AUTOSAR XML (schema 4-3-0)
package /Impl_SWC_INP_ARPkg
  swc implementation Impl_SWC_INP_type: programming-language=C, sw-version=1.0.0, vendor-id=0, behavior=SWC_INP_type_IB
    code-descriptors:
      code SRC: artifact-descriptors=autosar-engineering-object={short-label=EngObject, category=SWSRC}
    resource consumption ResourceConsumption
      memory section Mem_SWC_INP_CAL: size=0, sw-addrmethod=CAL, symbol=CAL
      memory section Mem_SWC_INP_CODE: size=0, sw-addrmethod=CODE, symbol=CODE
package /Impl_Type_INP_ARPkg
  18 x impl type:
    BINP_CAN1_outputs: category=STRUCTURE
      134 x element, all with category=TYPE_REFERENCE:
        VINP_CANMsgValidABM1_flg: implementation-data-type=boolean
        VINP_CANMsgValidEPB1_flg: implementation-data-type=boolean
        VINP_CANMsgValidEPS1_flg: implementation-data-type=boolean
        VINP_CANMsgValidESC1_flg: implementation-data-type=boolean
        VINP_CANMsgValidESC5_flg: implementation-data-type=boolean
        VINP_CANMsgValideBST1_flg: implementation-data-type=boolean
        VINP_ABM1CSErr_flg: implementation-data-type=boolean
        VINP_ABM1RCErr_flg: implementation-data-type=boolean
        VINP_ABMPassengerODSSta_flg: implementation-data-type=boolean
        VINP_ABMRearPassengerCTRODSSta_flg: implementation-data-type=boolean
        VINP_ABMRearPassengerLHODSSta_flg: implementation-data-type=boolean
        VINP_ABMRearPassengerRHODSSta_flg: implementation-data-type=boolean
        VINP_AirBagFailCmd_flg: implementation-data-type=boolean
        VINP_ChecksumABM1_enum: implementation-data-type=uint8
        VINP_CrashOutputSts_enum: implementation-data-type=uint8
        VINP_DriverSeatBeltCmd_flg: implementation-data-type=boolean
        VINP_LifeCountABM1_enum: implementation-data-type=uint8
        VINP_PABSwitchCmd_flg: implementation-data-type=boolean
        VINP_PsngrSeatBeltCmd_flg: implementation-data-type=boolean
        VINP_RCenterSeatBeltCmd_flg: implementation-data-type=boolean
        VINP_RDriverSeatBeltCmd_flg: implementation-data-type=boolean
        VINP_RPsngrSeatBeltCmd_flg: implementation-data-type=boolean
        VINP_TLHPsngrSeatBeltCmd_flg: implementation-data-type=boolean
        VINP_TRHPsngrSeatBeltCmd_flg: implementation-data-type=boolean
        VINP_EPB1CSErr_flg: implementation-data-type=boolean
        VINP_EPB1RCErr_flg: implementation-data-type=boolean
        VINP_DOASta_flg: implementation-data-type=boolean
        VINP_EPB1RC_enum: implementation-data-type=uint8
        VINP_EPBCarWashMode_flg: implementation-data-type=boolean
        VINP_EPBErrSta_enum: implementation-data-type=uint8
        VINP_EPBExtApplyAvail_flg: implementation-data-type=boolean
        VINP_EPBExtReleaseAvail_flg: implementation-data-type=boolean
        VINP_EPBSta_enum: implementation-data-type=uint8
        VINP_EPS1CSErr_flg: implementation-data-type=boolean
        VINP_EPS1RCErr_flg: implementation-data-type=boolean
        VINP_DriIntend_enum: implementation-data-type=uint8
        VINP_EPSAOIControl_enum: implementation-data-type=uint8
        VINP_EPSRC_enum: implementation-data-type=uint8
        VINP_EpasFailed_enum: implementation-data-type=uint8
        VINP_SASAngle_Deg: implementation-data-type=float32
        VINP_SASCAL_flg: implementation-data-type=boolean
        VINP_SASSpeed_degps: implementation-data-type=float32
        VINP_SASSpeedValid_flg: implementation-data-type=boolean
        VINP_SASV_flg: implementation-data-type=boolean
        VINP_ESC1CSErr_flg: implementation-data-type=boolean
        VINP_ESC1RCErr_flg: implementation-data-type=boolean
        VINP_ABSActive_flg: implementation-data-type=boolean
        VINP_ABSFailed_flg: implementation-data-type=boolean
        VINP_ABSWnlmpSta_flg: implementation-data-type=boolean
        VINP_AVHActive_flg: implementation-data-type=boolean
        VINP_AVHFailed_flg: implementation-data-type=boolean
        VINP_AmberWnlmpSta_flg: implementation-data-type=boolean
        VINP_BTCSActive_flg: implementation-data-type=boolean
        VINP_EBDActive_flg: implementation-data-type=boolean
        VINP_EBDFailed_flg: implementation-data-type=boolean
        VINP_ESC1CS_enum: implementation-data-type=uint8
        VINP_ESC1RC_enum: implementation-data-type=uint8
        VINP_ESCActive_flg: implementation-data-type=boolean
        VINP_ESCBeepReq_flg: implementation-data-type=boolean
        VINP_ESCFailed_flg: implementation-data-type=boolean
        VINP_ESCOFFStatus_enum: implementation-data-type=uint8
        VINP_ESCOfflmpSta_flg: implementation-data-type=boolean
        VINP_ESCWnlmpSta_enum: implementation-data-type=uint8
        VINP_ESSActive_flg: implementation-data-type=boolean
        VINP_FrPTCSActive_flg: implementation-data-type=boolean
        VINP_FrntAxlTrqReqDrv_Nm: implementation-data-type=float32
        VINP_GRADE_Deg: implementation-data-type=float32
        VINP_HBBActive_flg: implementation-data-type=boolean
        VINP_HBBFailed_flg: implementation-data-type=boolean
        VINP_HDDActive_flg: implementation-data-type=boolean
        VINP_HDDFailed_flg: implementation-data-type=boolean
        VINP_HSAActive_flg: implementation-data-type=boolean
        VINP_HSAFailed_flg: implementation-data-type=boolean
        VINP_LFPulseCount_enum: implementation-data-type=uint8
        VINP_LFPulseCountV_flg: implementation-data-type=boolean
        VINP_LFRawWhlSpeed_kph: implementation-data-type=float32
        VINP_LFRawWhlSpeedV_flg: implementation-data-type=boolean
        VINP_LFWhlRotDir_enum: implementation-data-type=uint8
        VINP_LRPulseCount_enum: implementation-data-type=uint8
        VINP_LRPulseCountV_flg: implementation-data-type=boolean
        VINP_LRRawWhlSpeed_kph: implementation-data-type=float32
        VINP_LRRawWhlSpeedV_flg: implementation-data-type=boolean
        VINP_LRWhlRotDir_enum: implementation-data-type=uint8
        VINP_PBAActive_flg: implementation-data-type=boolean
        VINP_PBAFailed_flg: implementation-data-type=boolean
        VINP_RFPulseCount_enum: implementation-data-type=uint8
        VINP_RFPulseCountV_flg: implementation-data-type=boolean
        VINP_RFRawWhlSpeed_kph: implementation-data-type=float32
        VINP_RFRawWhlSpeedV_flg: implementation-data-type=boolean
        VINP_RFWhlRotDir_enum: implementation-data-type=uint8
        VINP_RRPulseCount_enum: implementation-data-type=uint8
        VINP_RRPulseCountV_flg: implementation-data-type=boolean
        VINP_RRRawWhlSpeed_kph: implementation-data-type=float32
        VINP_RRRawWhlSpeedV_flg: implementation-data-type=boolean
        VINP_RRWhlRotDir_enum: implementation-data-type=uint8
        VINP_RearAxlTrqReqDrv_Nm: implementation-data-type=float32
        VINP_RedWnlmpSta_flg: implementation-data-type=boolean
        VINP_RrPTCSActive_flg: implementation-data-type=boolean
        VINP_TCSActive_flg: implementation-data-type=boolean
        VINP_TCSFailed_flg: implementation-data-type=boolean
        VINP_VehSpeed_kph: implementation-data-type=float32
        VINP_ESC5CSErr_flg: implementation-data-type=boolean
        VINP_ESC5RCErr_flg: implementation-data-type=boolean
        VINP_ACCAvail_flg: implementation-data-type=boolean
        VINP_AEBAvail_flg: implementation-data-type=boolean
        VINP_ActBrkLampSta_flg: implementation-data-type=boolean
        VINP_BrkDiscTempSta_flg: implementation-data-type=boolean
        VINP_BrkPedalPos_pct: implementation-data-type=float32
        VINP_BrkPedalPosSta_flg: implementation-data-type=boolean
        VINP_BrkSwSta_flg: implementation-data-type=boolean
        VINP_BrkSwV_flg: implementation-data-type=boolean
        VINP_ESC5CS_enum: implementation-data-type=uint8
        VINP_ESC5RC_enum: implementation-data-type=uint8
        VINP_ESCADASSta_enum: implementation-data-type=uint8
        VINP_ESCAPSSta_enum: implementation-data-type=uint8
        VINP_ESCStandstill_flg: implementation-data-type=boolean
        VINP_FrRBCActive_flg: implementation-data-type=boolean
        VINP_FrntAxlTrqReqBrk_Nm: implementation-data-type=float32
        VINP_LatAccel_Gps: implementation-data-type=float32
        VINP_LatAccelV_flg: implementation-data-type=boolean
        VINP_LongAccel_Gps: implementation-data-type=float32
        VINP_LongAccelV_flg: implementation-data-type=boolean
        VINP_MCPressure_bar: implementation-data-type=float32
        VINP_MCPressureV_flg: implementation-data-type=boolean
        VINP_MeterIndVehSpeed_kph: implementation-data-type=float32
        VINP_RDCActive_enum: implementation-data-type=uint8
        VINP_RearAxlTrqReqBrk_Nm: implementation-data-type=float32
        VINP_RrRBCActive_flg: implementation-data-type=boolean
        VINP_YawRate_degps: implementation-data-type=float32
        VINP_YawRateV_flg: implementation-data-type=boolean
        VINP_LowBrakeFluidSta_flg: implementation-data-type=boolean
        VINP_eBSTAmberWnlmpSta_flg: implementation-data-type=boolean
        VINP_eBSTBeepReq_flg: implementation-data-type=boolean
        VINP_eBSTRedWnlmpSta_flg: implementation-data-type=boolean
    BINP_CAN2_outputs: category=STRUCTURE
      196 x element, all with category=TYPE_REFERENCE:
        VINP_CANMsgValidHMI1_flg: implementation-data-type=boolean
        VINP_CANMsgValidIVI{1..3}_flg: implementation-data-type=boolean
        VINP_CANMsgValidMETER1_flg: implementation-data-type=boolean
        VINP_HMIACAirIntMCmd_flg: implementation-data-type=boolean
        VINP_HMIACAirIntPCmd_flg: implementation-data-type=boolean
        VINP_HMIACAutoBtnCmd_flg: implementation-data-type=boolean
        VINP_HMIACBtnCmd_flg: implementation-data-type=boolean
        VINP_HMIACFrDefogBtnCmd_flg: implementation-data-type=boolean
        VINP_HMIACRecycleBtnCmd_flg: implementation-data-type=boolean
        VINP_HMIACWindDirMCmd_flg: implementation-data-type=boolean
        VINP_HMIACWindDirPCmd_flg: implementation-data-type=boolean
        VINP_HMIAutoInterLightCmd_flg: implementation-data-type=boolean
        VINP_HMIBCMPostDefogBtnCmd_flg: implementation-data-type=boolean
        VINP_HMIZLSetTMCmd_flg: implementation-data-type=boolean
        VINP_HMIZLSetTPCmd_flg: implementation-data-type=boolean
        VINP_HMIZRSetTMCmd_flg: implementation-data-type=boolean
        VINP_HMIZRSetTPCmd_flg: implementation-data-type=boolean
        VINP_AmbLighLowBatAlertSW_flg: implementation-data-type=boolean
        VINP_AmbLighSafetyAlertSW_flg: implementation-data-type=boolean
        VINP_AmbLightBrightnessSet_enum: implementation-data-type=uint8
        VINP_AmbLightColorSet_enum: implementation-data-type=uint8
        VINP_AmbLightDimInDarkSW_flg: implementation-data-type=boolean
        VINP_AmbLightSW_flg: implementation-data-type=boolean
        VINP_AmbLightWlcmLightSW_flg: implementation-data-type=boolean
        VINP_FCPFrEvtBtnACMaxReq_flg: implementation-data-type=boolean
        VINP_FCPFrEvtBtnACReq_flg: implementation-data-type=boolean
        VINP_FCPFrEvtBtnAutoReq_flg: implementation-data-type=boolean
        VINP_FCPFrEvtBtnSyncReq_flg: implementation-data-type=boolean
        VINP_IVIAutoWipHSpdSWCmd_flg: implementation-data-type=boolean
        VINP_IVICLWinLockDoorSWSta_flg: implementation-data-type=boolean
        VINP_IVICreateAccReqSta_enum: implementation-data-type=uint8
        VINP_IVIDelAccReqSta_enum: implementation-data-type=uint8
        VINP_IVIDrivingLockSWSta_flg: implementation-data-type=boolean
        VINP_IVIEPSForceCmd_enum: implementation-data-type=uint8
        VINP_IVIFrTrunkUnlockReqSta_flg: implementation-data-type=boolean
        VINP_IVILinkAccReqSta_flg: implementation-data-type=boolean
        VINP_IVILinkAccSta_enum: implementation-data-type=uint8
        VINP_IVILinkKeySta_enum: implementation-data-type=uint8
        VINP_IVILocatedSTA_enum: implementation-data-type=uint8
        VINP_IVILockSoundSWSta_flg: implementation-data-type=boolean
        VINP_IVIMirrorFoldedSWSta_flg: implementation-data-type=boolean
        VINP_IVISWCVibModeSta_enum: implementation-data-type=uint8
        VINP_IVISilentChrgAlertSta_flg: implementation-data-type=boolean
        VINP_IVIStoppingUnlockSWSta_flg: implementation-data-type=boolean
        VINP_IVITimeCheck_enum: implementation-data-type=uint8
        VINP_IVITimeDay_DAY: implementation-data-type=float32
        VINP_IVITimeHour_hr: implementation-data-type=float32
        VINP_IVITimeMinute_min: implementation-data-type=float32
        VINP_IVITimeMonth_MONTH: implementation-data-type=float32
        VINP_IVITimeSecond_s: implementation-data-type=float32
        VINP_IVITimeYear_YEAR: implementation-data-type=float32
        VINP_IVIWPTCSWSta_flg: implementation-data-type=boolean
        VINP_IVIsigScreenReqSta_flg: implementation-data-type=boolean
        VINP_LINKtoDrive_flg: implementation-data-type=boolean
        VINP_OpenDrOpenWdoSW_flg: implementation-data-type=boolean
        VINP_PWCONTINUEUSE_flg: implementation-data-type=boolean
        VINP_SmartEcoModeSW_flg: implementation-data-type=boolean
        VINP_UserSet_enum: implementation-data-type=uint8
        VINP_ACChgCurSet_A: implementation-data-type=float32
        VINP_AVMErrSTA_flg: implementation-data-type=boolean
        VINP_AVMOFFRecButt_flg: implementation-data-type=boolean
        VINP_AVMParkingmode_enum: implementation-data-type=uint8
        VINP_AVMparkingcancel_enum: implementation-data-type=uint8
        VINP_AVMparkingexcute_enum: implementation-data-type=uint8
        VINP_ApproachUnlockSW_flg: implementation-data-type=boolean
        VINP_CAASSw_enum: implementation-data-type=uint8
        VINP_CDLLockButt_flg: implementation-data-type=boolean
        VINP_CDLUnlockButt_flg: implementation-data-type=boolean
        VINP_DSEATantiset_flg: implementation-data-type=boolean
        VINP_DSEATentryfunset_flg: implementation-data-type=boolean
        VINP_DSEATventreq_enum: implementation-data-type=uint8
        VINP_Distanceunit_flg: implementation-data-type=boolean
        VINP_ESCSWCmd_enum: implementation-data-type=uint8
        VINP_FSOffSw_enum: implementation-data-type=uint8
        VINP_FollowMeSW_flg: implementation-data-type=boolean
        VINP_GPSLAT_s: implementation-data-type=float32
        VINP_GPSLONG_enum: implementation-data-type=uint32
        VINP_HeadLampSW_enum: implementation-data-type=uint8
        VINP_HoodLatchSW_enum: implementation-data-type=uint8
        VINP_IVIACCAdaptiveSta_flg: implementation-data-type=boolean
        VINP_IVIAirIntZ3Cmd_enum: implementation-data-type=uint8
        VINP_IVICarWashModeCmd_flg: implementation-data-type=boolean
        VINP_IVIChargePortSWSta_flg: implementation-data-type=boolean
        VINP_IVICreepSWReq_flg: implementation-data-type=boolean
        VINP_IVIDSEATHeaterCmd_enum: implementation-data-type=uint8
        VINP_IVIDSEATFroEdgeHeightCmd_enum: implementation-data-type=uint8
        VINP_IVIDSEATHeightCmd_enum: implementation-data-type=uint8
        VINP_IVIDSEATMemory1Sta_flg: implementation-data-type=boolean
        VINP_IVIDSEATMemory2Sta_flg: implementation-data-type=boolean
        VINP_IVIDSEATMemoryOPTCLSSta_flg: implementation-data-type=boolean
        VINP_IVIDSEATReclineCmd_enum: implementation-data-type=uint8
        VINP_IVIDSEATSlideCmd_enum: implementation-data-type=uint8
        VINP_IVIFGSAirIntCmd_enum: implementation-data-type=uint8
        VINP_IVIFGSChCmd_enum: implementation-data-type=uint8
        VINP_IVIIONSWCmd_flg: implementation-data-type=boolean
        VINP_IVIISAOffsetSpd_enum: implementation-data-type=uint8
        VINP_IVINightModeSta_flg: implementation-data-type=boolean
        VINP_IVIPSEATHeaterCmd_enum: implementation-data-type=uint8
        VINP_IVIPSEATReclineCmd_enum: implementation-data-type=uint8
        VINP_IVIPSEATSlideCmd_enum: implementation-data-type=uint8
        VINP_IVIPTGModeSW_enum: implementation-data-type=uint8
        VINP_IVIPTGOpenHeight_enum: implementation-data-type=uint8
        VINP_IVIPTGStaSW_enum: implementation-data-type=uint8
        VINP_IVIPTGUSStaSW_flg: implementation-data-type=boolean
        VINP_IVIPWModeReq_enum: implementation-data-type=uint8
        VINP_IVIPwrLockSW_enum: implementation-data-type=uint8
        VINP_IVIPwroffreq_flg: implementation-data-type=boolean
        VINP_IVIRRDefReq_flg: implementation-data-type=boolean
        VINP_IVIReqV2L_enum: implementation-data-type=uint8
        VINP_IVISWCRUndefinedSta_enum: implementation-data-type=uint8
        VINP_IVIScreen_enum: implementation-data-type=uint8
        VINP_IVIStartChgreq_flg: implementation-data-type=boolean
        VINP_IVIStatus_flg: implementation-data-type=boolean
        VINP_IVIStopChgreq_flg: implementation-data-type=boolean
        VINP_IVITrailerCheckReqSta_flg: implementation-data-type=boolean
        VINP_IVITrailerModeSWSta_flg: implementation-data-type=boolean
        VINP_IVITriggerreq_flg: implementation-data-type=boolean
        VINP_IVIUnlockChgreq_flg: implementation-data-type=boolean
        VINP_IVIWIMAINSW_flg: implementation-data-type=boolean
        VINP_LDrvControlCommand_pct: implementation-data-type=float32
        VINP_LPasControlCommand_pct: implementation-data-type=float32
        VINP_LRLDControlCommand_pct: implementation-data-type=float32
        VINP_LRRDControlCommand_pct: implementation-data-type=float32
        VINP_LightShowStartReq_flg: implementation-data-type=boolean
        VINP_LightShowStopReq_flg: implementation-data-type=boolean
        VINP_MFRDNBrightReq_pct: implementation-data-type=float32
        VINP_OFFACMODE_enum: implementation-data-type=uint8
        VINP_PSEATventreq_enum: implementation-data-type=uint8
        VINP_PerdV2L_enum: implementation-data-type=uint8
        VINP_RFogLampSW_flg: implementation-data-type=boolean
        VINP_RollModeSWCmd_enum: implementation-data-type=uint8
        VINP_RoomLampMode_flg: implementation-data-type=boolean
        VINP_SOCADJBUTT_flg: implementation-data-type=boolean
        VINP_SOCLimitSet_pct: implementation-data-type=float32
        VINP_SOCV2LLimit_pct: implementation-data-type=float32
        VINP_SchedChgStart_flg: implementation-data-type=boolean
        VINP_SchedChgStop_flg: implementation-data-type=boolean
        VINP_SchedChgbutt_flg: implementation-data-type=boolean
        VINP_SchedChglimit_pct: implementation-data-type=float32
        VINP_SchedChgwake_flg: implementation-data-type=boolean
        VINP_SenstivityPosition_enum: implementation-data-type=uint8
        VINP_SetUnlockSingle_flg: implementation-data-type=boolean
        VINP_TCSSWCmd_enum: implementation-data-type=uint8
        VINP_TPMSCaliButt_flg: implementation-data-type=boolean
        VINP_TPMSResButt_flg: implementation-data-type=boolean
        VINP_TurnSwTimeSet_enum: implementation-data-type=uint8
        VINP_WalkawayLockSW_flg: implementation-data-type=boolean
        VINP_WlcmLightMode_enum: implementation-data-type=uint8
        VINP_sigAirIntenZon1Req_enum: implementation-data-type=uint8
        VINP_sigDfrstReq_flg: implementation-data-type=boolean
        VINP_sigFaceReq_flg: implementation-data-type=boolean
        VINP_sigFootReq_flg: implementation-data-type=boolean
        VINP_sigRecircReq_flg: implementation-data-type=boolean
        VINP_sigSetTempZon1Req_C: implementation-data-type=float32
        VINP_sigSetTempZon2Req_C: implementation-data-type=float32
        VINP_IVICLBlowerYSta_pct: implementation-data-type=float32
        VINP_IVICLBlowerZSta_pct: implementation-data-type=float32
        VINP_IVICRBlowerYSta_pct: implementation-data-type=float32
        VINP_IVICRBlowerZSta_pct: implementation-data-type=float32
        VINP_IVIHMICustmiFunSta_enum: implementation-data-type=uint8
        VINP_IVIHMICustmiKEYSta_enum: implementation-data-type=uint8
        VINP_IVILBlowerModeSta_enum: implementation-data-type=uint8
        VINP_IVILBlowerYSta_pct: implementation-data-type=float32
        VINP_IVILBlowerZSta_pct: implementation-data-type=float32
        VINP_IVILSEATventCmd_enum: implementation-data-type=uint8
        VINP_IVIMLFMostCmd_flg: implementation-data-type=boolean
        VINP_IVIMLFootLiftCmd_enum: implementation-data-type=uint8
        VINP_IVIMLNapModeCmd_flg: implementation-data-type=boolean
        VINP_IVIMLReclinerCmd_enum: implementation-data-type=uint8
        VINP_IVIMLRestoreCmd_flg: implementation-data-type=boolean
        VINP_IVIMLSEATventCmd_enum: implementation-data-type=uint8
        VINP_IVIMLSeatLiftCmd_enum: implementation-data-type=uint8
        VINP_IVIMLSldRestoreCmd_flg: implementation-data-type=boolean
        VINP_IVIMLSliderCmd_enum: implementation-data-type=uint8
        VINP_IVIMLZeroGravityCmd_flg: implementation-data-type=boolean
        VINP_IVIMRFMostCmd_flg: implementation-data-type=boolean
        VINP_IVIMRFootLiftCmd_enum: implementation-data-type=uint8
        VINP_IVIMRNapModeCmd_flg: implementation-data-type=boolean
        VINP_IVIMRReclinerCmd_enum: implementation-data-type=uint8
        VINP_IVIMRRestoreCmd_flg: implementation-data-type=boolean
        VINP_IVIMRSEATventCmd_enum: implementation-data-type=uint8
        VINP_IVIMRSeatLiftCmd_enum: implementation-data-type=uint8
        VINP_IVIMRSldRestoreCmd_flg: implementation-data-type=boolean
        VINP_IVIMRSliderCmd_enum: implementation-data-type=uint8
        VINP_IVIMRZeroGravityCmd_flg: implementation-data-type=boolean
        VINP_IVIRBlowerModeSta_enum: implementation-data-type=uint8
        VINP_IVIRBlowerYSta_pct: implementation-data-type=float32
        VINP_IVIRBlowerZSta_pct: implementation-data-type=float32
        VINP_IVIRSEATventCmd_enum: implementation-data-type=uint8
        VINP_IVISnowModeCmd_flg: implementation-data-type=boolean
        VINP_IVIUserTakeOverAPSSta_flg: implementation-data-type=boolean
        VINP_IVIZon1WindDirSWReqSta_flg: implementation-data-type=boolean
        VINP_METERKPHCalcu_kph: implementation-data-type=float32
        VINP_ODOMETER_km: implementation-data-type=float32
    BINP_CAN3_outputs: category=STRUCTURE
      298 x element, all with category=TYPE_REFERENCE:
        VINP_CANMsgValidBMS1_flg: implementation-data-type=boolean
        VINP_CANMsgValidBMS{3..6}_flg: implementation-data-type=boolean
        VINP_CANMsgValidBMS8_flg: implementation-data-type=boolean
        VINP_CANMsgValidCCU1_flg: implementation-data-type=boolean
        VINP_CANMsgValidCCU2_flg: implementation-data-type=boolean
        VINP_CANMsgValidEBM1_flg: implementation-data-type=boolean
        VINP_CANMsgValidMCUBF1_flg: implementation-data-type=boolean
        VINP_CANMsgValidMCUBF2_flg: implementation-data-type=boolean
        VINP_CANMsgValidMCUBR1_flg: implementation-data-type=boolean
        VINP_CANMsgValidMCUBR2_flg: implementation-data-type=boolean
        VINP_CANMsgValidMCUNF{1..3}_flg: implementation-data-type=boolean
        VINP_CANMsgValidMCUNR{1..3}_flg: implementation-data-type=boolean
        VINP_CANMsgValidShifter1_flg: implementation-data-type=boolean
        VINP_CANMsgValidShifter2_flg: implementation-data-type=boolean
        VINP_BMS1CSErr_flg: implementation-data-type=boolean
        VINP_BMS1RCErr_flg: implementation-data-type=boolean
        VINP_BMSChckSum1_enum: implementation-data-type=uint8
        VINP_BMSRolCnct1_enum: implementation-data-type=uint8
        VINP_HVBPwrAvailChrg_kW: implementation-data-type=float32
        VINP_HVBPwrAvailChrg30_kW: implementation-data-type=float32
        VINP_HVBPwrAvailChrg60_kW: implementation-data-type=float32
        VINP_HVBPwrAvailDchrg_kW: implementation-data-type=float32
        VINP_HVBPwrAvailDchrg30_kW: implementation-data-type=float32
        VINP_HVBPwrAvailDchrg60_kW: implementation-data-type=float32
        VINP_HVBattCurr_A: implementation-data-type=float32
        VINP_HVBattVolt_V: implementation-data-type=float32
        VINP_ACChrgCurrDis_A: implementation-data-type=float32
        VINP_FireDetErr_flg: implementation-data-type=boolean
        VINP_HVBChrgPwr_kWh: implementation-data-type=float32
        VINP_HVBChrgPwrTotal_kWh: implementation-data-type=float32
        VINP_HVBDrvPwr_kWh: implementation-data-type=float32
        VINP_HVBDrvPwrTotal_kWh: implementation-data-type=float32
        VINP_HVBFullChrgPwr_kWh: implementation-data-type=float32
        VINP_HVBIsoImpedenceN_Megaohm: implementation-data-type=float32
        VINP_HVBIsoImpedenceP_Megaohm: implementation-data-type=float32
        VINP_HVBSOH_pct: implementation-data-type=float32
        VINP_HVBattErr_flg: implementation-data-type=boolean
        VINP_HVBattPackVolt_V: implementation-data-type=float32
        VINP_HVBattSOC_pct: implementation-data-type=float32
        VINP_HVBattSOCDis_pct: implementation-data-type=float32
        VINP_RemainChrgTime_min: implementation-data-type=float32
        VINP_CellTempAvg_C: implementation-data-type=float32
        VINP_HVBCellVoltMax_mV: implementation-data-type=float32
        VINP_HVBCellVoltMin_mV: implementation-data-type=float32
        VINP_HVBMTempMax_C: implementation-data-type=float32
        VINP_HVBMTempMin_C: implementation-data-type=float32
        VINP_MaxCellTempNum_enum: implementation-data-type=uint8
        VINP_MaxCellVoltNum_enum: implementation-data-type=uint8
        VINP_MinCellTempNum_enum: implementation-data-type=uint8
        VINP_MinCellVoltNum_enum: implementation-data-type=uint8
        VINP_HVInVolt_V: implementation-data-type=float32
        VINP_LVBattDet12V_V: implementation-data-type=float32
        VINP_OBCACCSLimit_A: implementation-data-type=float32
        VINP_OBCDCCurLm_A: implementation-data-type=float32
        VINP_OBCDCVoltLm_V: implementation-data-type=float32
        VINP_BMS6CSErr_flg: implementation-data-type=boolean
        VINP_BMS6RCErr_flg: implementation-data-type=boolean
        VINP_BMSChckSum_enum: implementation-data-type=uint8
        VINP_BMSRolCnct_enum: implementation-data-type=uint8
        VINP_BMSREADY_flg: implementation-data-type=boolean
        VINP_BMSWarn{1..8}_flg: implementation-data-type=boolean
        VINP_ChrgInLockReq_enum: implementation-data-type=uint8
        VINP_ChrgPlugSta_enum: implementation-data-type=uint8
        VINP_DisChrgPlugErr_enum: implementation-data-type=uint8
        VINP_ExtChrgSta_enum: implementation-data-type=uint8
        VINP_HVBChrgErr_enum: implementation-data-type=uint8
        VINP_HVBContactorSta_flg: implementation-data-type=boolean
        VINP_HVBHVILErr_flg: implementation-data-type=boolean
        VINP_HVBOvrTempErr_flg: implementation-data-type=boolean
        VINP_HVBOvrTempWarn_enum: implementation-data-type=uint8
        VINP_HVBPreheatPrecoolSta_enum: implementation-data-type=uint8
        VINP_HVBattReady4Pre_enum: implementation-data-type=uint8
        VINP_HVILSta_flg: implementation-data-type=boolean
        VINP_V2LSta_enum: implementation-data-type=uint8
        VINP_MainRlyNegSta_enum: implementation-data-type=uint8
        VINP_MainRlyPosSta_enum: implementation-data-type=uint8
        VINP_CCU1CSErr_flg: implementation-data-type=boolean
        VINP_CCU1RCErr_flg: implementation-data-type=boolean
        VINP_CSCCU1_enum: implementation-data-type=uint8
        VINP_DCDCAuxCur_A: implementation-data-type=float32
        VINP_DCDCAuxVolt_V: implementation-data-type=float32
        VINP_DCDCHVCur_A: implementation-data-type=float32
        VINP_DCDCInVoltInf_V: implementation-data-type=float32
        VINP_DCDCPreCompleted_enum: implementation-data-type=uint8
        VINP_OBCDCCurrInf_A: implementation-data-type=float32
        VINP_OBCDCVoltInf_V: implementation-data-type=float32
        VINP_OBCPreCompleted_enum: implementation-data-type=uint8
        VINP_OBCWakeup4Plugin_flg: implementation-data-type=boolean
        VINP_RCCCU1_enum: implementation-data-type=uint8
        VINP_CCU2CSErr_flg: implementation-data-type=boolean
        VINP_CCU2RCErr_flg: implementation-data-type=boolean
        VINP_CSCCU2_enum: implementation-data-type=uint8
        VINP_DCDCEnaSta_flg: implementation-data-type=boolean
        VINP_DCDCFaultSta_enum: implementation-data-type=uint8
        VINP_DCDCReady4Pre_flg: implementation-data-type=boolean
        VINP_DCDCTemp_C: implementation-data-type=float32
        VINP_OBCACCurrInf_A: implementation-data-type=float32
        VINP_OBCACVoltInf_V: implementation-data-type=float32
        VINP_OBCEnaSta_flg: implementation-data-type=boolean
        VINP_OBCFaultSta_enum: implementation-data-type=uint8
        VINP_OBCPluginSta_flg: implementation-data-type=boolean
        VINP_OBCReady4Pre_flg: implementation-data-type=boolean
        VINP_OBCTemp_C: implementation-data-type=float32
        VINP_OBCV2LSta_enum: implementation-data-type=uint8
        VINP_OBCACCurLim_enum: implementation-data-type=uint8
        VINP_RCCCU2_enum: implementation-data-type=uint8
        VINP_EBMErrSta_enum: implementation-data-type=uint8
        VINP_EBMRLampSta_enum: implementation-data-type=uint8
        VINP_MCUBF1CSErr_flg: implementation-data-type=boolean
        VINP_MCUBF1RCErr_flg: implementation-data-type=boolean
        VINP_FrActvDmpDisabSta_flg: implementation-data-type=boolean
        VINP_FrEDUDrtSta_flg: implementation-data-type=boolean
        VINP_FrEDUOpratingSta_flg: implementation-data-type=boolean
        VINP_FrEDURealTMTq_Nm: implementation-data-type=float32
        VINP_FrEDURotateDirction_enum: implementation-data-type=uint8
        VINP_FrEDUTqReqFbk_Nm: implementation-data-type=float32
        VINP_FrMCU1Chksum_enum: implementation-data-type=uint8
        VINP_FrMCU1RolCnt_enum: implementation-data-type=uint8
        VINP_FrMCUBAT_V: implementation-data-type=float32
        VINP_FrMCUDCBusCurr_A: implementation-data-type=float32
        VINP_FrMCUDCBusVolt_V: implementation-data-type=float32
        VINP_FrMCUDischrgSta_flg: implementation-data-type=boolean
        VINP_FrMCUEnaSta_flg: implementation-data-type=boolean
        VINP_FrMCUErr_enum: implementation-data-type=uint8
        VINP_FrMCUIGNsta_flg: implementation-data-type=boolean
        VINP_FrMCUReady_flg: implementation-data-type=boolean
        VINP_FrMCUReady4Pre_flg: implementation-data-type=boolean
        VINP_FrMCUSysSta_enum: implementation-data-type=uint8
        VINP_FrMCUTemp_C: implementation-data-type=float32
        VINP_FrMotorAvailTq_Nm: implementation-data-type=float32
        VINP_FrRegenAvailTq_Nm: implementation-data-type=float32
        VINP_FrTMSpd_rpm: implementation-data-type=float32
        VINP_FrTMTemp_C: implementation-data-type=float32
        VINP_FrTMid_A: implementation-data-type=float32
        VINP_FrTMiq_A: implementation-data-type=float32
        VINP_MCUWarnF_enum: implementation-data-type=uint8
        VINP_MCUBFRealPwrKwSta_kW: implementation-data-type=float32
        VINP_FrCoolanttempReq_C: implementation-data-type=float32
        VINP_FrFailcode1_enum: implementation-data-type=uint8
        VINP_FrFailcode2_enum: implementation-data-type=uint8
        VINP_FrFailcodehistory1_enum: implementation-data-type=uint8
        VINP_FrFailcodehistory2_enum: implementation-data-type=uint8
        VINP_FrLLCTemp_C: implementation-data-type=float32
        VINP_FrLLCflowReq_Lpmin: implementation-data-type=float32
        VINP_FrMCUTempWarn_enum: implementation-data-type=uint8
        VINP_FrMCUHWVer_enum: implementation-data-type=uint16
        VINP_FrMCUSWVer_enum: implementation-data-type=uint16
        VINP_FrTMTempWarn_enum: implementation-data-type=uint8
        VINP_MCUBFLLCTempWarnSta_enum: implementation-data-type=uint8
        VINP_MCUBR1CSErr_flg: implementation-data-type=boolean
        VINP_MCUBR1RCErr_flg: implementation-data-type=boolean
        VINP_MCUWarnR_enum: implementation-data-type=uint8
        VINP_MCUBRRealPwrKwSta_kW: implementation-data-type=float32
        VINP_RrActvDmpDisabSta_flg: implementation-data-type=boolean
        VINP_RrEDUDrtSta_flg: implementation-data-type=boolean
        VINP_RrEDUOpratingSta_flg: implementation-data-type=boolean
        VINP_RrEDURealTMTq_Nm: implementation-data-type=float32
        VINP_RrEDURotateDirction_enum: implementation-data-type=uint8
        VINP_RrEDUTqReqFbk_Nm: implementation-data-type=float32
        VINP_RrMCU1Chksum_enum: implementation-data-type=uint8
        VINP_RrMCU1RolCnt_enum: implementation-data-type=uint8
        VINP_RrMCUBAT_V: implementation-data-type=float32
        VINP_RrMCUDCBusCurr_A: implementation-data-type=float32
        VINP_RrMCUDCBusVolt_V: implementation-data-type=float32
        VINP_RrMCUDischrgSta_flg: implementation-data-type=boolean
        VINP_RrMCUEnaSta_flg: implementation-data-type=boolean
        VINP_RrMCUErr_enum: implementation-data-type=uint8
        VINP_RrMCUIGNsta_flg: implementation-data-type=boolean
        VINP_RrMCUReady_flg: implementation-data-type=boolean
        VINP_RrMCUReady4Pre_flg: implementation-data-type=boolean
        VINP_RrMCUSysSta_enum: implementation-data-type=uint8
        VINP_RrMCUTemp_C: implementation-data-type=float32
        VINP_RrMotorAvailTq_Nm: implementation-data-type=float32
        VINP_RrRegenAvailTq_Nm: implementation-data-type=float32
        VINP_RrTMSpd_rpm: implementation-data-type=float32
        VINP_RrTMTemp_C: implementation-data-type=float32
        VINP_RrTMid_A: implementation-data-type=float32
        VINP_RrTMiq_A: implementation-data-type=float32
        VINP_MCUBRLLCTempWarnSta_enum: implementation-data-type=uint8
        VINP_RrCoolanttempReq_cnt: implementation-data-type=float32
        VINP_RrFailcode1_enum: implementation-data-type=uint8
        VINP_RrFailcode2_enum: implementation-data-type=uint8
        VINP_RrFailcodehistory1_enum: implementation-data-type=uint8
        VINP_RrFailcodehistory2_enum: implementation-data-type=uint8
        VINP_RrLLCTemp_C: implementation-data-type=float32
        VINP_RrLLCflowReq_Lpmin: implementation-data-type=float32
        VINP_RrMCU3HWVer_enum: implementation-data-type=uint16
        VINP_RrMCU3SWVer_enum: implementation-data-type=uint16
        VINP_RrMCUTempWarn_enum: implementation-data-type=uint8
        VINP_RrTMTempWarn_enum: implementation-data-type=uint8
        VINP_MCUNF1CSErr_flg: implementation-data-type=boolean
        VINP_MCUNF1RCErr_flg: implementation-data-type=boolean
        VINP_FrActvDmpDisabStaNidec_flg: implementation-data-type=boolean
        VINP_FrEDUDrtStaNidec_flg: implementation-data-type=boolean
        VINP_FrEDUOpratingStaNidec_flg: implementation-data-type=boolean
        VINP_FrEDURealTMTqNidec_Nm: implementation-data-type=float32
        VINP_FrEDURotateDirctionNidec_enum: implementation-data-type=uint8
        VINP_FrEDUTqReqFbkNidec_Nm: implementation-data-type=float32
        VINP_FrMCU1ChksumNidec_enum: implementation-data-type=uint8
        VINP_FrMCU1RolCntNidec_enum: implementation-data-type=uint8
        VINP_FrMCUBATNidec_V: implementation-data-type=float32
        VINP_FrMCUDCBusCurrNidec_A: implementation-data-type=float32
        VINP_FrMCUDCBusVoltNidec_V: implementation-data-type=float32
        VINP_FrMCUDischrgStaNidec_flg: implementation-data-type=boolean
        VINP_FrMCUEnaStaNidec_flg: implementation-data-type=boolean
        VINP_FrMCUErrNidec_enum: implementation-data-type=uint8
        VINP_FrMCUIGNstaNidec_flg: implementation-data-type=boolean
        VINP_FrMCUReady4PreNidec_flg: implementation-data-type=boolean
        VINP_FrMCUReadyNidec_flg: implementation-data-type=boolean
        VINP_FrMCUSysStaNidec_enum: implementation-data-type=uint8
        VINP_FrMCUTempNidec_C: implementation-data-type=float32
        VINP_FrMotorAvailTqNidec_Nm: implementation-data-type=float32
        VINP_FrRegenAvailTqNidec_Nm: implementation-data-type=float32
        VINP_FrTMSpdNidec_rpm: implementation-data-type=float32
        VINP_FrTMTempNidec_C: implementation-data-type=float32
        VINP_FrTMidNidec_A: implementation-data-type=float32
        VINP_FrTMiqNidec_A: implementation-data-type=float32
        VINP_MCUWarnFNidec_enum: implementation-data-type=uint8
        VINP_FrCoolanttempReqNidec_C: implementation-data-type=float32
        VINP_FrEOPSpdSetNidec_rpm: implementation-data-type=float32
        VINP_FrFailcode1Nidec_enum: implementation-data-type=uint8
        VINP_FrFailcode2Nidec_enum: implementation-data-type=uint8
        VINP_FrFailcodehistory1Nidec_enum: implementation-data-type=uint8
        VINP_FrFailcodehistory2Nidec_enum: implementation-data-type=uint8
        VINP_FrLLCTempNidec_C: implementation-data-type=float32
        VINP_FrLLCflowReqNidec_Lpmin: implementation-data-type=float32
        VINP_FrMCUTempWarnNidec_enum: implementation-data-type=uint8
        VINP_FrTMTempWarnNidec_enum: implementation-data-type=uint8
        VINP_FrMCUHWVerNidec_enum: implementation-data-type=uint16
        VINP_FrMCUSWVerNidec_enum: implementation-data-type=uint16
        VINP_MCUNR1CSErr_flg: implementation-data-type=boolean
        VINP_MCUNR1RCErr_flg: implementation-data-type=boolean
        VINP_MCUWarnRNidec_enum: implementation-data-type=uint8
        VINP_RrActvDmpDisabStaNidec_flg: implementation-data-type=boolean
        VINP_RrEDUDrtStaNidec_flg: implementation-data-type=boolean
        VINP_RrEDUOpratingStaNidec_flg: implementation-data-type=boolean
        VINP_RrEDURealTMTqNidec_Nm: implementation-data-type=float32
        VINP_RrEDURotateDirctionNidec_enum: implementation-data-type=uint8
        VINP_RrEDUTqReqFbkNidec_Nm: implementation-data-type=float32
        VINP_RrMCU1ChksumNidec_enum: implementation-data-type=uint8
        VINP_RrMCU1RolCntNidec_enum: implementation-data-type=uint8
        VINP_RrMCUBATNidec_V: implementation-data-type=float32
        VINP_RrMCUDCBusCurrNidec_A: implementation-data-type=float32
        VINP_RrMCUDCBusVoltNidec_V: implementation-data-type=float32
        VINP_RrMCUDischrgStaNidec_flg: implementation-data-type=boolean
        VINP_RrMCUEnaStaNidec_flg: implementation-data-type=boolean
        VINP_RrMCUErrNidec_enum: implementation-data-type=uint8
        VINP_RrMCUIGNstaNidec_flg: implementation-data-type=boolean
        VINP_RrMCUReady4PreNidec_flg: implementation-data-type=boolean
        VINP_RrMCUReadyNidec_flg: implementation-data-type=boolean
        VINP_RrMCUSysStaNidec_enum: implementation-data-type=uint8
        VINP_RrMCUTempNidec_C: implementation-data-type=float32
        VINP_RrMotorAvailTqNidec_Nm: implementation-data-type=float32
        VINP_RrRegenAvailTqNidec_Nm: implementation-data-type=float32
        VINP_RrTMSpdNidec_rpm: implementation-data-type=float32
        VINP_RrTMTempNidec_C: implementation-data-type=float32
        VINP_RrTMidNidec_A: implementation-data-type=float32
        VINP_RrTMiqNidec_A: implementation-data-type=float32
        VINP_RrCoolanttempReqNidec_cnt: implementation-data-type=float32
        VINP_RrEOPSpdSetNidec_rpm: implementation-data-type=float32
        VINP_RrFailcode1Nidec_enum: implementation-data-type=uint8
        VINP_RrFailcode2Nidec_enum: implementation-data-type=uint8
        VINP_RrFailcodehistory1Nidec_enum: implementation-data-type=uint8
        VINP_RrFailcodehistory2Nidec_enum: implementation-data-type=uint8
        VINP_RrLLCTempNidec_C: implementation-data-type=float32
        VINP_RrLLCflowReqNidec_Lpmin: implementation-data-type=float32
        VINP_RrMCUTempWarnNidec_enum: implementation-data-type=uint8
        VINP_RrTMTempWarnNidec_enum: implementation-data-type=uint8
        VINP_RrMCU3HWVerNidec_enum: implementation-data-type=uint16
        VINP_RrMCU3SWVerNidec_enum: implementation-data-type=uint16
        VINP_Shifter1CSErr_flg: implementation-data-type=boolean
        VINP_Shifter1RCErr_flg: implementation-data-type=boolean
        VINP_ShifterCRC8_enum: implementation-data-type=uint8
        VINP_ShifterFailsta_enum: implementation-data-type=uint8
        VINP_ShifterHandleCmd_enum: implementation-data-type=uint8
        VINP_ShifterRC_enum: implementation-data-type=uint8
        VINP_Shifter2CSErr_flg: implementation-data-type=boolean
        VINP_Shifter2RCErr_flg: implementation-data-type=boolean
        VINP_CSW2DimSwSta_flg: implementation-data-type=boolean
        VINP_CSW2FWasSwSta_enum: implementation-data-type=uint8
        VINP_CSW2FWipSwSta_enum: implementation-data-type=uint8
        VINP_CSW2PassSWSta_flg: implementation-data-type=boolean
        VINP_CSW2RWipWasSwSta_enum: implementation-data-type=uint8
        VINP_CSW2TurnSwSta_enum: implementation-data-type=uint8
    BINP_CAN4_outputs: category=STRUCTURE
      272 x element, all with category=TYPE_REFERENCE:
        VINP_CANMsgValidBodyZoneDR1_flg: implementation-data-type=boolean
        VINP_CANMsgValidBodyZoneDR2_flg: implementation-data-type=boolean
        VINP_CANMsgValidBodyZonePS1_flg: implementation-data-type=boolean
        VINP_CANMsgValidBodyZonePS2_flg: implementation-data-type=boolean
        VINP_CANMsgValidDKC1_flg: implementation-data-type=boolean
        VINP_CANMsgValidDKC2_flg: implementation-data-type=boolean
        VINP_CANMsgValidPTG1_flg: implementation-data-type=boolean
        VINP_CANMsgValidZONEDR1_flg: implementation-data-type=boolean
        VINP_CANMsgValidZONEDRVCU_flg: implementation-data-type=boolean
        VINP_CANMsgValidZONEFR1_flg: implementation-data-type=boolean
        VINP_CANMsgValidZONEFRVCU_flg: implementation-data-type=boolean
        VINP_CANMsgValidzGWAPTC1_flg: implementation-data-type=boolean
        VINP_CANMsgValidzGWCANFr1_flg: implementation-data-type=boolean
        VINP_CANMsgValidzGWLINDr1_flg: implementation-data-type=boolean
        VINP_CANMsgValidzGWLINDr2_flg: implementation-data-type=boolean
        VINP_CANMsgValidzGWLINFr1_flg: implementation-data-type=boolean
        VINP_CANMsgValidzGWLINFr2_flg: implementation-data-type=boolean
        VINP_CANMsgValidzGWSEAT1_flg: implementation-data-type=boolean
        VINP_BDDSEATAntiSta_flg: implementation-data-type=boolean
        VINP_BDDSEATEntryFunSta_flg: implementation-data-type=boolean
        VINP_BDDSEATErrorSta_flg: implementation-data-type=boolean
        VINP_BDDSEATMemSetSta_enum: implementation-data-type=uint8
        VINP_BDDSEATModeSta_enum: implementation-data-type=uint8
        VINP_BDDSEATVentSta_enum: implementation-data-type=uint8
        VINP_BDDSEATheaterSta_enum: implementation-data-type=uint8
        VINP_BDAPMWinFOpenedSta_pct: implementation-data-type=float32
        VINP_BDAPMWinROpenedSta_pct: implementation-data-type=float32
        VINP_BDDoorFHandleCloseSta_flg: implementation-data-type=boolean
        VINP_BDDoorRHandleCloseSta_flg: implementation-data-type=boolean
        VINP_BPPSEATErrorSta_flg: implementation-data-type=boolean
        VINP_BPPSEATModeSta_enum: implementation-data-type=uint8
        VINP_BPPSEATVentSta_enum: implementation-data-type=uint8
        VINP_BPPSEATheaterSta_enum: implementation-data-type=uint8
        VINP_BPPTGActiveSta_enum: implementation-data-type=uint8
        VINP_BPPTGExistSta_flg: implementation-data-type=boolean
        VINP_BPPTGInsideSW1Sta_enum: implementation-data-type=uint8
        VINP_BPPTGInsideSW2Sta_enum: implementation-data-type=uint8
        VINP_BPPTGIsSetHeightSta_flg: implementation-data-type=boolean
        VINP_BPPTGLeftHallPosnSta_enum: implementation-data-type=uint16
        VINP_BPPTGOpenRatioSta_pct: implementation-data-type=float32
        VINP_BPPTGRDILCmd_enum: implementation-data-type=uint8
        VINP_BPPTGSysSta_enum: implementation-data-type=uint8
        VINP_BPAPMWinFOpenedSta_pct: implementation-data-type=float32
        VINP_BPAPMWinROpenedSta_pct: implementation-data-type=float32
        VINP_BPDoorFHandleCloseSta_flg: implementation-data-type=boolean
        VINP_BPDoorRHandleCloseSta_flg: implementation-data-type=boolean
        VINP_BPSEATLVentSta_enum: implementation-data-type=uint8
        VINP_BPSEATMLVentSta_enum: implementation-data-type=uint8
        VINP_BPSEATMRVentSta_enum: implementation-data-type=uint8
        VINP_BPSEATRVentSta_enum: implementation-data-type=uint8
        VINP_DKCKeyNumSta_enum: implementation-data-type=uint8
        VINP_DKCKeyTypeSta_enum: implementation-data-type=uint8
        VINP_DKCPDkeyAreaRAPSSta_enum: implementation-data-type=uint8
        VINP_DKCParkingModeCmd_enum: implementation-data-type=uint8
        VINP_DKCReVehData_enum: implementation-data-type=uint8
        VINP_PCommandToBCM_enum: implementation-data-type=uint8
        VINP_PCommandToPTG_enum: implementation-data-type=uint8
        VINP_PDKeyAreaLockUnlock_enum: implementation-data-type=uint8
        VINP_PDKeyAreaPS_enum: implementation-data-type=uint8
        VINP_PDKeyAreaPTG_enum: implementation-data-type=uint8
        VINP_PDKeyWelcome_enum: implementation-data-type=uint8
        VINP_PDkeyShowIVI_enum: implementation-data-type=uint8
        VINP_PKeyMiss_flg: implementation-data-type=boolean
        VINP_PKeyMode_enum: implementation-data-type=uint8
        VINP_PUIDLowPower_flg: implementation-data-type=boolean
        VINP_EncryptionDATA063_enum: implementation-data-type=uint64
        VINP_EncryptionDATA64127_enum: implementation-data-type=uint64
        VINP_RandomNumberX_enum: implementation-data-type=uint64
        VINP_PTGActiveSta_enum: implementation-data-type=uint8
        VINP_PTGAutoStaus_flg: implementation-data-type=boolean
        VINP_PTGExist_flg: implementation-data-type=boolean
        VINP_PTGHWVer_enum: implementation-data-type=uint8
        VINP_PTGInnerSW2_enum: implementation-data-type=uint8
        VINP_PTGIsSetHeight_flg: implementation-data-type=boolean
        VINP_PTGOpenRatio_pct: implementation-data-type=float32
        VINP_PTGRDILSta_enum: implementation-data-type=uint8
        VINP_PTGSWVer_enum: implementation-data-type=uint8
        VINP_PTGSysSta_enum: implementation-data-type=uint8
        VINP_DrLockSta_flg: implementation-data-type=boolean
        VINP_MIRRORFOLDSW_flg: implementation-data-type=boolean
        VINP_RLTurnLPErr_flg: implementation-data-type=boolean
        VINP_RLTurnLampC_mA: implementation-data-type=float32
        VINP_RRTurnLPErr_flg: implementation-data-type=boolean
        VINP_RRTurnLampC_mA: implementation-data-type=float32
        VINP_RWiperAS_flg: implementation-data-type=boolean
        VINP_RWiperProtection_flg: implementation-data-type=boolean
        VINP_BlowerErr_enum: implementation-data-type=uint8
        VINP_DrPMMLVOutPErrLmp_flg: implementation-data-type=boolean
        VINP_DrPMMSysErrLmp_flg: implementation-data-type=boolean
        VINP_DrSCPSysErrLmp_flg: implementation-data-type=boolean
        VINP_DrStdAErrSta_flg: implementation-data-type=boolean
        VINP_LeftHallPos_enum: implementation-data-type=uint16
        VINP_SolarL_W: implementation-data-type=float32
        VINP_SolarLErr_enum: implementation-data-type=uint8
        VINP_SolarR_W: implementation-data-type=float32
        VINP_SolarRErr_enum: implementation-data-type=uint8
        VINP_TFaceL_C: implementation-data-type=float32
        VINP_TFaceLErr_enum: implementation-data-type=uint8
        VINP_TFaceR_C: implementation-data-type=float32
        VINP_TFaceRErr_enum: implementation-data-type=uint8
        VINP_TFaceRr_C: implementation-data-type=float32
        VINP_TFaceRrErr_enum: implementation-data-type=uint8
        VINP_TFootL_C: implementation-data-type=float32
        VINP_TFootLErr_enum: implementation-data-type=uint8
        VINP_TFootR_C: implementation-data-type=float32
        VINP_TFootRErr_enum: implementation-data-type=uint8
        VINP_TFootRr_C: implementation-data-type=float32
        VINP_TFootRrErr_enum: implementation-data-type=uint8
        VINP_Tevap_C: implementation-data-type=float32
        VINP_TevapErr_enum: implementation-data-type=uint8
        VINP_Tincar_C: implementation-data-type=float32
        VINP_TincarErr_enum: implementation-data-type=uint8
        VINP_ZoneDrMalfunLevel_enum: implementation-data-type=uint8
        VINP_ChargeInletLockSta_flg: implementation-data-type=boolean
        VINP_CompProEN_flg: implementation-data-type=boolean
        VINP_FLTurnLPErr_flg: implementation-data-type=boolean
        VINP_FLTurnLampC_mA: implementation-data-type=float32
        VINP_FLTurnLightWarning_flg: implementation-data-type=boolean
        VINP_FRTurnLPErr_flg: implementation-data-type=boolean
        VINP_FRTurnLampC_mA: implementation-data-type=float32
        VINP_FRTurnLightWarning_flg: implementation-data-type=boolean
        VINP_FWiperAS_flg: implementation-data-type=boolean
        VINP_FWiperProtection_flg: implementation-data-type=boolean
        VINP_LADBHibeamIndication_flg: implementation-data-type=boolean
        VINP_LADBOperationStatus_flg: implementation-data-type=boolean
        VINP_LADBWarning_flg: implementation-data-type=boolean
        VINP_LAHBWarning_flg: implementation-data-type=boolean
        VINP_LDRLWarning_flg: implementation-data-type=boolean
        VINP_LLBWarning_flg: implementation-data-type=boolean
        VINP_LpositionLampWarning_flg: implementation-data-type=boolean
        VINP_RADBHibeamIndication_flg: implementation-data-type=boolean
        VINP_RADBOperationStatus_flg: implementation-data-type=boolean
        VINP_RADBWarning_flg: implementation-data-type=boolean
        VINP_RAHBWarning_flg: implementation-data-type=boolean
        VINP_RDRLWarning_flg: implementation-data-type=boolean
        VINP_RLBWarning_flg: implementation-data-type=boolean
        VINP_RpositionLampWarning_flg: implementation-data-type=boolean
        VINP_TrailerCheck_flg: implementation-data-type=boolean
        VINP_TrailerModeSta_enum: implementation-data-type=uint8
        VINP_ZFRBCMChargerDoorSWSta_flg: implementation-data-type=boolean
        VINP_ZFRBCMHRLTurnLPNormalSta_flg: implementation-data-type=boolean
        VINP_ZFRBCMHRRTurnLPHNormalSta_flg: implementation-data-type=boolean
        VINP_ZFRTHCMCLEVentActYSta_pct: implementation-data-type=float32
        VINP_ZFRTHCMCREVentActYSta_pct: implementation-data-type=float32
        VINP_ZFRTHCMLEVentActYSta_pct: implementation-data-type=float32
        VINP_ZFRTHCMREVentActYSta_pct: implementation-data-type=float32
        VINP_AGSErr_enum: implementation-data-type=uint8
        VINP_BatInTemp_C: implementation-data-type=float32
        VINP_BatInTempErr_enum: implementation-data-type=uint8
        VINP_BatOutTemp_C: implementation-data-type=float32
        VINP_COMPErr_enum: implementation-data-type=uint8
        VINP_EACProtectEnable_enum: implementation-data-type=uint8
        VINP_EWP3Err_enum: implementation-data-type=uint8
        VINP_EXV1Err_enum: implementation-data-type=uint8
        VINP_EXV2Err_enum: implementation-data-type=uint8
        VINP_FanErr_enum: implementation-data-type=uint8
        VINP_FrPMMLimpHomeActReq_flg: implementation-data-type=boolean
        VINP_MotorInTemp_C: implementation-data-type=float32
        VINP_MotorInTempErr_enum: implementation-data-type=uint8
        VINP_MotorOutTemp_C: implementation-data-type=float32
        VINP_MotorOutTempErr_enum: implementation-data-type=uint8
        VINP_PTHighP_KPa: implementation-data-type=float32
        VINP_PTHighPErr_enum: implementation-data-type=uint8
        VINP_PTHighTact_C: implementation-data-type=float32
        VINP_PTHighTactErr_enum: implementation-data-type=uint8
        VINP_PTLowP1_KPa: implementation-data-type=float32
        VINP_PTLowP1Err_enum: implementation-data-type=uint8
        VINP_PTLowP2_KPa: implementation-data-type=float32
        VINP_PTLowP2Err_enum: implementation-data-type=uint8
        VINP_PTLowT1_C: implementation-data-type=float32
        VINP_PTLowT1Err_enum: implementation-data-type=uint8
        VINP_PTLowT2_C: implementation-data-type=float32
        VINP_PTLowT2Err_enum: implementation-data-type=uint8
        VINP_SOTXVErr_enum: implementation-data-type=uint8
        VINP_SOV{1..3}Err_enum: implementation-data-type=uint8
        VINP_Tamb_C: implementation-data-type=float32
        VINP_TambErr_enum: implementation-data-type=uint8
        VINP_FrntPTCLeActHeatPwr_W: implementation-data-type=float32
        VINP_FrntPTCRearLeActHeatPwr_W: implementation-data-type=float32
        VINP_FrntPTCRearRiActHeatPwr_W: implementation-data-type=float32
        VINP_FrntPTCRiActHeatPwr_W: implementation-data-type=float32
        VINP_COMPActualPwr_W: implementation-data-type=float32
        VINP_COMPConCur_A: implementation-data-type=float32
        VINP_COMPConVolt_V: implementation-data-type=float32
        VINP_COMPStatorSpd_rpm: implementation-data-type=float32
        VINP_PTC1PowerConsumption_kW: implementation-data-type=float32
        VINP_CSWDimSw_flg: implementation-data-type=boolean
        VINP_CSWFWasSwSta_enum: implementation-data-type=uint8
        VINP_CSWFWipSwSta_enum: implementation-data-type=uint8
        VINP_CSWPassSWSta_flg: implementation-data-type=boolean
        VINP_CSWRWasSWSta_enum: implementation-data-type=uint8
        VINP_CSWRWipIntSwSta_enum: implementation-data-type=uint8
        VINP_CSWTurnSwSta_enum: implementation-data-type=uint8
        VINP_FAPWL01LINResponseError_flg: implementation-data-type=boolean
        VINP_LDrvMotorRelayError_flg: implementation-data-type=boolean
        VINP_LDrvMotorRippleError_flg: implementation-data-type=boolean
        VINP_LDrvValWdwOpened_pct: implementation-data-type=float32
        VINP_LDrvWdwPositionSts_enum: implementation-data-type=uint8
        VINP_LPasMotorRelayError_flg: implementation-data-type=boolean
        VINP_LPasMotorRippleError_flg: implementation-data-type=boolean
        VINP_LPasValWdwOpened_pct: implementation-data-type=float32
        VINP_LPasWdwPositionSts_enum: implementation-data-type=uint8
        VINP_LRLDMotorRelayError_flg: implementation-data-type=boolean
        VINP_LRLDMotorRippleError_flg: implementation-data-type=boolean
        VINP_LRLDValWdwOpened_pct: implementation-data-type=float32
        VINP_LRLDWdwPositionSts_enum: implementation-data-type=uint8
        VINP_LRRDMotorRelayError_flg: implementation-data-type=boolean
        VINP_LRRDMotorRippleError_flg: implementation-data-type=boolean
        VINP_LRRDValWdwOpened_pct: implementation-data-type=float32
        VINP_LRRDWdwPositionSts_enum: implementation-data-type=uint8
        VINP_RAPWL01LINResponseError_flg: implementation-data-type=boolean
        VINP_RLSLampSta_flg: implementation-data-type=boolean
        VINP_RLSRainSnrWiperCmd_enum: implementation-data-type=uint8
        VINP_SWC2LADASSta_flg: implementation-data-type=boolean
        VINP_SWC2LDriveModeSta_flg: implementation-data-type=boolean
        VINP_SWC2LHomeSta_flg: implementation-data-type=boolean
        VINP_SWC2LLeftSta_flg: implementation-data-type=boolean
        VINP_SWC2LRegenUpSta_flg: implementation-data-type=boolean
        VINP_SWC2LRightSta_flg: implementation-data-type=boolean
        VINP_SWC2LScrollDownSta_flg: implementation-data-type=boolean
        VINP_SWC2LScrollPressSta_flg: implementation-data-type=boolean
        VINP_SWC2LScrollUpSta_flg: implementation-data-type=boolean
        VINP_SWC2RCustomizeSta_flg: implementation-data-type=boolean
        VINP_SWC2RLeftSta_flg: implementation-data-type=boolean
        VINP_SWC2RPageSwitchSta_flg: implementation-data-type=boolean
        VINP_SWC2RRegenDownSta_flg: implementation-data-type=boolean
        VINP_SWC2RRightSta_flg: implementation-data-type=boolean
        VINP_SWC2RScrollDownSta_flg: implementation-data-type=boolean
        VINP_SWC2RScrollPressSta_flg: implementation-data-type=boolean
        VINP_SWC2RScrollUpSta_flg: implementation-data-type=boolean
        VINP_SWC2RVRSta_flg: implementation-data-type=boolean
        VINP_SWCACCSta_flg: implementation-data-type=boolean
        VINP_SWCCANCELSta_flg: implementation-data-type=boolean
        VINP_SWCDistanceSta_flg: implementation-data-type=boolean
        VINP_SWCDownSta_flg: implementation-data-type=boolean
        VINP_SWCLKASta_flg: implementation-data-type=boolean
        VINP_SWCLeftSta_flg: implementation-data-type=boolean
        VINP_SWCRegenDown_flg: implementation-data-type=boolean
        VINP_SWCRegenUp_flg: implementation-data-type=boolean
        VINP_SWCResUpSta_flg: implementation-data-type=boolean
        VINP_SWCRightSta_flg: implementation-data-type=boolean
        VINP_SWCSetdownSta_flg: implementation-data-type=boolean
        VINP_SWCTripSta_flg: implementation-data-type=boolean
        VINP_SWCUndefinedSta_flg: implementation-data-type=boolean
        VINP_SWCUpSta_flg: implementation-data-type=boolean
        VINP_SWCVRSta_flg: implementation-data-type=boolean
        VINP_SWCmodeSta_flg: implementation-data-type=boolean
        VINP_ACT1ResponseError_flg: implementation-data-type=boolean
        VINP_AGSActualPosition_enum: implementation-data-type=uint8
        VINP_FGSIntenRspSta_enum: implementation-data-type=uint8
        VINP_EWP1BlockError_enum: implementation-data-type=uint8
        VINP_EWP1OverCurrError_enum: implementation-data-type=uint8
        VINP_EWP2BlockError_enum: implementation-data-type=uint8
        VINP_EWP2OverCurrError_enum: implementation-data-type=uint8
        VINP_EWP3BlockError_enum: implementation-data-type=uint8
        VINP_EWP3OverCurrError_enum: implementation-data-type=uint8
        VINP_DSEATAntiSta_flg: implementation-data-type=boolean
        VINP_DSEATEntryFunSta_flg: implementation-data-type=boolean
        VINP_DSEATErrorSta_flg: implementation-data-type=boolean
        VINP_DSEATHWVer_enum: implementation-data-type=uint16
        VINP_DSEATMode_enum: implementation-data-type=uint8
        VINP_DSEATSWVer_enum: implementation-data-type=uint16
        VINP_DSEATVentSta_enum: implementation-data-type=uint8
        VINP_DSEATheatersta_enum: implementation-data-type=uint8
        VINP_PSEATErrorSta_flg: implementation-data-type=boolean
        VINP_PSEATHWVer_enum: implementation-data-type=uint16
        VINP_PSEATMode_enum: implementation-data-type=uint8
        VINP_PSEATSWVer_enum: implementation-data-type=uint16
        VINP_PSEATVentSta_enum: implementation-data-type=uint8
        VINP_PSEATheatersta_enum: implementation-data-type=uint8
    BINP_CAN5_outputs: category=STRUCTURE
      21 x element, all with category=TYPE_REFERENCE:
        VINP_CANMsgValidTBOX2_flg: implementation-data-type=boolean
        VINP_CANMsgValidTBOX3_flg: implementation-data-type=boolean
        VINP_TimeSyncFromBSDay_DAY: implementation-data-type=float32
        VINP_TimeSyncFromBSHour_hr: implementation-data-type=float32
        VINP_TimeSyncFromBSMinute_min: implementation-data-type=float32
        VINP_TimeSyncFromBSMonth_MONTH: implementation-data-type=float32
        VINP_TimeSyncFromBSSecond_s: implementation-data-type=float32
        VINP_TimeSyncFromBSYear_YEAR: implementation-data-type=float32
        VINP_ChargePercentSet_pct: implementation-data-type=float32
        VINP_ReserveChargeOFFDay_DAY: implementation-data-type=float32
        VINP_ReserveChargeOFFHour_hr: implementation-data-type=float32
        VINP_ReserveChargeOFFMinute_min: implementation-data-type=float32
        VINP_ReserveChargeOFFMonth_MONTH: implementation-data-type=float32
        VINP_ReserveChargeOFFYear_YEAR: implementation-data-type=float32
        VINP_ReserveChargeOnDay_DAY: implementation-data-type=float32
        VINP_ReserveChargeOnHour_hr: implementation-data-type=float32
        VINP_ReserveChargeOnMinute_min: implementation-data-type=float32
        VINP_ReserveChargeOnMonth_MONTH: implementation-data-type=float32
        VINP_ReserveChargeOnYear_YEAR: implementation-data-type=float32
        VINP_TBOXHWVER_enum: implementation-data-type=uint32
        VINP_TBOXSWVER_enum: implementation-data-type=uint32
    BINP_CAN6_outputs: category=STRUCTURE
      99 x element, all with category=TYPE_REFERENCE:
        VINP_CANMsgValidFCM{1..4}_flg: implementation-data-type=boolean
        VINP_CANMsgValidSRR1_flg: implementation-data-type=boolean
        VINP_ACCComfortBandLower_mps2: implementation-data-type=float32
        VINP_ACCComfortBandUpper_mps2: implementation-data-type=float32
        VINP_ACCJerkLowerLimit_mps3: implementation-data-type=float32
        VINP_ACCJerkUpperLimit_mps3: implementation-data-type=float32
        VINP_ACCObjDist_m: implementation-data-type=float32
        VINP_ACCObjDstLvl_enum: implementation-data-type=uint8
        VINP_ACCObjRelSpd_mps: implementation-data-type=float32
        VINP_ACCRequiredAccel_mps2: implementation-data-type=float32
        VINP_ACCTakeoverReq_flg: implementation-data-type=boolean
        VINP_ACCVehHoldReq_flg: implementation-data-type=boolean
        VINP_ADASACCSta_enum: implementation-data-type=uint8
        VINP_ADASAEBReq_enum: implementation-data-type=uint8
        VINP_ADASAEBSta_enum: implementation-data-type=uint8
        VINP_ADASCAMSpdLim_enum: implementation-data-type=uint8
        VINP_ADASDBSReq_enum: implementation-data-type=uint8
        VINP_ADASFCWMute_flg: implementation-data-type=boolean
        VINP_ADASFCWSta_enum: implementation-data-type=uint8
        VINP_ADASFaultSta_flg: implementation-data-type=boolean
        VINP_ADASFltWrnReq_flg: implementation-data-type=boolean
        VINP_ADASForceIdle_flg: implementation-data-type=boolean
        VINP_ADASISASta_enum: implementation-data-type=uint8
        VINP_ADASLDWMute_flg: implementation-data-type=boolean
        VINP_ADASLDWSta_enum: implementation-data-type=uint8
        VINP_ADASLFCHandsOffWarning_enum: implementation-data-type=uint8
        VINP_ADASLFCSta_enum: implementation-data-type=uint8
        VINP_ADASLFCWarnSound_enum: implementation-data-type=uint8
        VINP_ADASLKASta_enum: implementation-data-type=uint8
        VINP_ADASLaneModeL_enum: implementation-data-type=uint8
        VINP_ADASLaneModeR_enum: implementation-data-type=uint8
        VINP_ADASLanecurveL_raw32: implementation-data-type=float32
        VINP_ADASLanecurveR_raw32: implementation-data-type=float32
        VINP_ADASLanetypeL_enum: implementation-data-type=uint8
        VINP_ADASLanetypeR_enum: implementation-data-type=uint8
        VINP_ADASSLIFSpdLim_enum: implementation-data-type=uint8
        VINP_ADASSLIFSta_enum: implementation-data-type=uint8
        VINP_ADASShftPosnReq_enum: implementation-data-type=uint8
        VINP_ADASShftPosnReqA_flg: implementation-data-type=boolean
        VINP_ADASVehSpdLim_enum: implementation-data-type=uint8
        VINP_ADASWarningMsg_enum: implementation-data-type=uint8
        VINP_AEBVehHoldReq_flg: implementation-data-type=boolean
        VINP_CameraBlockage_flg: implementation-data-type=boolean
        VINP_FCM1Checksum_enum: implementation-data-type=uint8
        VINP_FCM1LifeCount_enum: implementation-data-type=uint8
        VINP_FCMACCmode_enum: implementation-data-type=uint8
        VINP_FCMLKAStrToqReq_Nm: implementation-data-type=float32
        VINP_FCMLKATOIAct_enum: implementation-data-type=uint8
        VINP_FCMLKATOIFault_flg: implementation-data-type=boolean
        VINP_ForceLowBeam_enum: implementation-data-type=uint8
        VINP_HazardWarningReq_flg: implementation-data-type=boolean
        VINP_ISAWarningMsg_enum: implementation-data-type=uint8
        VINP_LKAHODDisplayWarning_flg: implementation-data-type=boolean
        VINP_LKAHODSoundWarning_flg: implementation-data-type=boolean
        VINP_LVDAACCStatusInformation_flg: implementation-data-type=boolean
        VINP_LVDADisabled_flg: implementation-data-type=boolean
        VINP_LVDAFailinfo_flg: implementation-data-type=boolean
        VINP_LVDAMuteSta_enum: implementation-data-type=uint8
        VINP_LVDAWarning_flg: implementation-data-type=boolean
        VINP_LeftTurnLightReq_flg: implementation-data-type=boolean
        VINP_RightTurnLightReq_flg: implementation-data-type=boolean
        VINP_TargetType_enum: implementation-data-type=uint8
        VINP_TimeGapLevel_enum: implementation-data-type=uint8
        VINP_FCM2CSErr_flg: implementation-data-type=boolean
        VINP_FCM2RCErr_flg: implementation-data-type=boolean
        VINP_ADBVehDst1Val_enum: implementation-data-type=uint8
        VINP_MELaneCurvDervLt_raw32: implementation-data-type=float32
        VINP_MELaneCurvDervLt2_raw32: implementation-data-type=float32
        VINP_MELaneCurvDervRt_raw32: implementation-data-type=float32
        VINP_MELaneCurvDervRt2_raw32: implementation-data-type=float32
        VINP_MELaneCurvLt_raw32: implementation-data-type=float32
        VINP_MELaneCurvLt2_raw32: implementation-data-type=float32
        VINP_MELaneCurvRt_raw32: implementation-data-type=float32
        VINP_MELaneCurvRt2_raw32: implementation-data-type=float32
        VINP_MELaneHeadAngLt_radians: implementation-data-type=float32
        VINP_MELaneHeadAngLt2_radians: implementation-data-type=float32
        VINP_MELaneHeadAngRt_radians: implementation-data-type=float32
        VINP_MELaneHeadAngRt2_radians: implementation-data-type=float32
        VINP_MELanePosLt_m: implementation-data-type=float32
        VINP_MELanePosLt2_m: implementation-data-type=float32
        VINP_MELanePosRt_m: implementation-data-type=float32
        VINP_MELanePosRt2_m: implementation-data-type=float32
        VINP_FCM4CSErr_flg: implementation-data-type=boolean
        VINP_FCM4RCErr_flg: implementation-data-type=boolean
        VINP_ADASAngCtrlTqWeightGain_pct: implementation-data-type=float32
        VINP_ADASDesStrWhlAngCtrlCmd_Deg: implementation-data-type=float32
        VINP_ADASDrvInputTqBoostAct_flg: implementation-data-type=boolean
        VINP_ADASDrvInputTqBoostGain_pct: implementation-data-type=float32
        VINP_ADASMaxAngCtrlOutTqLimit_Nm: implementation-data-type=float32
        VINP_ADASStrWhlAngCtrlStatus_flg: implementation-data-type=boolean
        VINP_SRRBSDWarnL_enum: implementation-data-type=uint8
        VINP_SRRBSDWarnR_enum: implementation-data-type=uint8
        VINP_SRRODASoundL_flg: implementation-data-type=boolean
        VINP_SRRODASoundR_flg: implementation-data-type=boolean
        VINP_SRRODAWarnL_enum: implementation-data-type=uint8
        VINP_SRRODAWarnR_enum: implementation-data-type=uint8
    BINP_APM_outputs: category=STRUCTURE
      58 x element, all with category=TYPE_REFERENCE:
        VINP_PASDRMR_cm: implementation-data-type=uint8
        VINP_PASDRML_cm: implementation-data-type=uint8
        VINP_PASDRCR_cm: implementation-data-type=uint8
        VINP_PASDRCL_cm: implementation-data-type=uint8
        VINP_PASDFMR_cm: implementation-data-type=uint8
        VINP_PASDFML_cm: implementation-data-type=uint8
        VINP_PASDFCR_cm: implementation-data-type=uint8
        VINP_PASDFCL_cm: implementation-data-type=uint8
        VINP_APSDRLR_cm: implementation-data-type=uint16
        VINP_APSDRLL_cm: implementation-data-type=uint16
        VINP_APSDFLR_cm: implementation-data-type=uint16
        VINP_APSDFLL_cm: implementation-data-type=uint16
        VINP_PASAFCL_enum: implementation-data-type=uint8
        VINP_PASARMR_enum: implementation-data-type=uint8
        VINP_PASARML_enum: implementation-data-type=uint8
        VINP_PASARCR_enum: implementation-data-type=uint8
        VINP_PASARCL_enum: implementation-data-type=uint8
        VINP_PASAFMR_enum: implementation-data-type=uint8
        VINP_PASAFML_enum: implementation-data-type=uint8
        VINP_PASAFCR_enum: implementation-data-type=uint8
        VINP_USSStaRMR_flg: implementation-data-type=boolean
        VINP_USSStaRML_flg: implementation-data-type=boolean
        VINP_USSStaRLR_flg: implementation-data-type=boolean
        VINP_USSStaRLL_flg: implementation-data-type=boolean
        VINP_USSStaRCR_flg: implementation-data-type=boolean
        VINP_USSStaRCL_flg: implementation-data-type=boolean
        VINP_USSStaFMR_flg: implementation-data-type=boolean
        VINP_USSStaFML_flg: implementation-data-type=boolean
        VINP_USSStaFLR_flg: implementation-data-type=boolean
        VINP_USSStaFLL_flg: implementation-data-type=boolean
        VINP_USSStaFCR_flg: implementation-data-type=boolean
        VINP_USSStaFCL_flg: implementation-data-type=boolean
        VINP_Chime_enum: implementation-data-type=uint8
        VINP_SNSRLayout_enum: implementation-data-type=uint8
        VINP_StaFSya_flg: implementation-data-type=boolean
        VINP_ModOperation_enum: implementation-data-type=uint8
        VINP_APSProgressPCT_pct: implementation-data-type=float32
        VINP_APSRQDisplay_enum: implementation-data-type=uint8
        VINP_APSSWVer_enum: implementation-data-type=uint8
        VINP_APSHWVer_enum: implementation-data-type=uint8
        VINP_APSExitCondition_enum: implementation-data-type=uint8
        VINP_APSAngleTarget_Deg: implementation-data-type=float32
        VINP_APSStaSystem_enum: implementation-data-type=uint8
        VINP_APSVRqEPASCtrl_flg: implementation-data-type=boolean
        VINP_APSRqEPASCtrl_flg: implementation-data-type=boolean
        VINP_APSReq_enum: implementation-data-type=uint8
        VINP_APSDecReq_mps2: implementation-data-type=float32
        VINP_APSDecReqA_flg: implementation-data-type=boolean
        VINP_APSShiftPosnReq_enum: implementation-data-type=uint8
        VINP_APSSpeedCMD_kph: implementation-data-type=float32
        VINP_APSVMCReqA_flg: implementation-data-type=boolean
        VINP_CAASSta_enum: implementation-data-type=uint8
        VINP_CAASVMCReqA_flg: implementation-data-type=boolean
        VINP_APSPwrReq_enum: implementation-data-type=uint8
        VINP_RAPSBCMLockReq_flg: implementation-data-type=boolean
        VINP_RAPSBCMLamp_enum: implementation-data-type=uint8
        VINP_RAPSErrWarnSta_enum: implementation-data-type=uint8
        VINP_RAPSErrLv1_flg: implementation-data-type=boolean
    BINP_DDM_outputs: category=STRUCTURE
      element VINP_ClearDTCcmd_flg: implementation-data-type=boolean
      element VINP_ClearZevDTCcmd_flg: implementation-data-type=boolean
    BINP_DKC_outputs: category=STRUCTURE
      39 x element, all with category=TYPE_REFERENCE:
        VINP_DKCDecReVehData_enum: implementation-data-type=uint8
        VINP_DKCDecRemotePW_enum: implementation-data-type=uint8
        VINP_DKCDecPCommandToBCM_enum: implementation-data-type=uint8
        VINP_DKCDecPCommandToPTG_enum: implementation-data-type=uint8
        VINP_DKCDecPDKeyAreaLockUnlock_enum: implementation-data-type=uint8
        VINP_DKCDecPDKeyAreaPS_enum: implementation-data-type=uint8
        VINP_DKCDecPDKeyAreaPTG_enum: implementation-data-type=uint8
        VINP_DKCDecPDKeyWelcome_enum: implementation-data-type=uint8
        VINP_DKCDecPDkeyShowIVI_enum: implementation-data-type=uint8
        VINP_DKCDecPKeyMiss_flg: implementation-data-type=boolean
        VINP_DKCDecPKeyMode_enum: implementation-data-type=uint8
        VINP_DKCDecPUIDLowPower_flg: implementation-data-type=boolean
        VINP_TimeSNDKCFbk_cnt: implementation-data-type=uint32
        VINP_DKCDecryptionFail_flg: implementation-data-type=boolean
        VINP_NFCDoorSta_flg: implementation-data-type=boolean
        VINP_NFCLidASta_flg: implementation-data-type=boolean
        VINP_KeyFobAreaU16_enum: implementation-data-type=uint16
        VINP_UIDButtonCmd_enum: implementation-data-type=uint8
        VINP_BTConnectSta_enum: implementation-data-type=uint8
        VINP_UIDBatVoltx1000_V: implementation-data-type=uint16
        VINP_DKCBTRSSI_dB: implementation-data-type=sint8
        VINP_UWB{1..5}Distance_cm: implementation-data-type=uint16
        VINP_UWB{1..5}Power_dB: implementation-data-type=sint8
        VINP_UWBpositionX_cm: implementation-data-type=sint16
        VINP_UWBpositionY_cm: implementation-data-type=sint16
        VINP_UWB{1..5}RangingSta_enum: implementation-data-type=uint8
        VINP_UWBRangingON_flg: implementation-data-type=boolean
    BINP_GPIO_outputs: category=STRUCTURE
      25 x element, all with category=TYPE_REFERENCE:
        VINP_AccelPedal1VolShortHigh_enum: implementation-data-type=uint8
        VINP_AccelPedal1VolShortLow_enum: implementation-data-type=uint8
        VINP_AccelPedal1Vol_V: implementation-data-type=float32
        VINP_AccelPedal1VolValid_flg: implementation-data-type=boolean
        VINP_AccelPedal2VolShortHigh_enum: implementation-data-type=uint8
        VINP_AccelPedal2VolShortLow_enum: implementation-data-type=uint8
        VINP_AccelPedal2Vol_V: implementation-data-type=float32
        VINP_AccelPedal2VolValid_flg: implementation-data-type=boolean
        VINP_BrakeSWGPIO_flg: implementation-data-type=boolean
        VINP_HoodSW_flg: implementation-data-type=boolean
        VINP_TailgateSW_flg: implementation-data-type=boolean
        VINP_DrDoorSW_flg: implementation-data-type=boolean
        VINP_PsDoorSW_flg: implementation-data-type=boolean
        VINP_RRDoorSW_flg: implementation-data-type=boolean
        VINP_RLDoorSW_flg: implementation-data-type=boolean
        VINP_CentralDoorLockSW_flg: implementation-data-type=boolean
        VINP_HazardSW_flg: implementation-data-type=boolean
        VINP_BrakeLampSW_flg: implementation-data-type=boolean
        VINP_TrunkHanSW_flg: implementation-data-type=boolean
        VINP_SeatSW_flg: implementation-data-type=boolean
        VINP_CrashSignalGPIO_flg: implementation-data-type=boolean
        VINP_HWID{1..4}_enum: implementation-data-type=uint8
    BINP_IMU_outputs: category=STRUCTURE
      12 x element, all with category=TYPE_REFERENCE, implementation-data-type=sint16:
        VINP_MemOffsetGyroX_raw16
        VINP_MemOffsetGyroY_raw16
        VINP_MemOffsetGyroZ_raw16
        VINP_MemOffsetAccX_raw16
        VINP_MemOffsetAccY_raw16
        VINP_MemOffsetAccZ_raw16
        VINP_SensingGyroX_raw16
        VINP_SensingGyroY_raw16
        VINP_SensingGyroZ_raw16
        VINP_SensingAccX_raw16
        VINP_SensingAccY_raw16
        VINP_SensingAccZ_raw16
    BINP_SYS_outputs: category=STRUCTURE
      328 x element, all with category=TYPE_REFERENCE:
        VINP_CarModel{1..3}_cnt: implementation-data-type=uint8
        VINP_ECU1_cnt: implementation-data-type=uint8
        VINP_ECU2_cnt: implementation-data-type=uint8
        VINP_Major1_cnt: implementation-data-type=uint8
        VINP_Major2_cnt: implementation-data-type=uint8
        VINP_Minor1_cnt: implementation-data-type=uint8
        VINP_Minor2_cnt: implementation-data-type=uint8
        VINP_Patch1_cnt: implementation-data-type=uint8
        VINP_Patch2_cnt: implementation-data-type=uint8
        VINP_Country1_cnt: implementation-data-type=uint8
        VINP_Country2_cnt: implementation-data-type=uint8
        VINP_Variation_cnt: implementation-data-type=uint8
        VINP_Dash1_cnt: implementation-data-type=uint8
        VINP_Change1_cnt: implementation-data-type=uint8
        VINP_Change2_cnt: implementation-data-type=uint8
        VINP_Dash2_cnt: implementation-data-type=uint8
        VINP_SHA{1..8}_cnt: implementation-data-type=uint8
        VINP_AcoreReadyToSlp_flg: implementation-data-type=boolean
        VINP_PwrReq_OTA_enum: implementation-data-type=uint8
        VINP_AllowMovThd_OTA_enum: implementation-data-type=uint8
        VINP_EvccAplusPwrUpReq_flg: implementation-data-type=boolean
        VINP_DrivetrainSelect_enum: implementation-data-type=uint8
        VINP_ReadFlashCorrect_flg: implementation-data-type=boolean
        VINP_FlashAntitheft_enum: implementation-data-type=uint8
        VINP_RandomnumberY_raw{1..8}: implementation-data-type=uint8
        VINP_FlashACModeMem_enum: implementation-data-type=uint8
        VINP_FlashFace_enum: implementation-data-type=uint8
        VINP_FlashFoot_enum: implementation-data-type=uint8
        VINP_FlashFrost_enum: implementation-data-type=uint8
        VINP_FlashFaceM_enum: implementation-data-type=uint8
        VINP_FlashFootM_enum: implementation-data-type=uint8
        VINP_FlashCCUSyncSts_enum: implementation-data-type=uint8
        VINP_FlashACForceOFF_flg: implementation-data-type=boolean
        VINP_FlashsigRecircSt_enum: implementation-data-type=uint8
        VINP_FlashRecAutoFlg_enum: implementation-data-type=uint8
        VINP_FlashAirIntenZone1M_enum: implementation-data-type=uint8
        VINP_Flashfdefog_enum: implementation-data-type=uint8
        VINP_FlashsigSetTempZon1St_C: implementation-data-type=uint8
        VINP_FlashsigSetTempZon2StM_C: implementation-data-type=uint8
        VINP_FlashCountAlarm_enum: implementation-data-type=uint8
        VINP_FlashMFSWTri_flg: implementation-data-type=boolean
        VINP_FlashMirrorFlodPos_flg: implementation-data-type=boolean
        VINP_FlashFuelDoorPos_flg: implementation-data-type=boolean
        VINP_FlashLockSetting_enum: implementation-data-type=uint8
        VINP_FlashMFRDNBrightReq_pct: implementation-data-type=uint8
        VINP_FlashRoomLampMode_enum: implementation-data-type=uint8
        VINP_FlashWiperFixMode_flg: implementation-data-type=boolean
        VINP_FlashIVIPTGUSStaSW_enum: implementation-data-type=uint8
        VINP_AnyNMID_flg: implementation-data-type=boolean
        VINP_CurrentNmState_enum: implementation-data-type=uint8
        VINP_NvmProtectSta_flg: implementation-data-type=boolean
        VINP_AuxBattVolmV_mV: implementation-data-type=uint16
        VINP_Pedal1Ref5V_V: implementation-data-type=float32
        VINP_Pedal2Ref5V_V: implementation-data-type=float32
        VINP_EAPS1MINMem_pct: implementation-data-type=float32
        VINP_EAPS2MINMem_pct: implementation-data-type=float32
        VINP_FlashHoodSW_flg: implementation-data-type=boolean
        VINP_FlashTailgateSW_flg: implementation-data-type=boolean
        VINP_FlashCTDLockSW_flg: implementation-data-type=boolean
        VINP_FlashTailgateHDSW_flg: implementation-data-type=boolean
        VINP_NetworkReqCalled_flg: implementation-data-type=boolean
        VINP_PmicBootReason_enum: implementation-data-type=uint8
        VINP_WisrBootReason_raw32: implementation-data-type=uint32
        VINP_FlashAPMDoorControlSta_flg: implementation-data-type=boolean
        VINP_AcoreRebootCmd_flg: implementation-data-type=boolean
        VINP_DIDGetDynoMode_flg: implementation-data-type=boolean
        VINP_CAN{1..6}BusOff_flg: implementation-data-type=boolean
        VINP_funAuto_flg: implementation-data-type=boolean
        VINP_DiagDRLOFF_flg: implementation-data-type=boolean
        VINP_DiagFMHT_s: implementation-data-type=float32
        VINP_DiagFLTC_mA: implementation-data-type=float32
        VINP_DiagFRTC_mA: implementation-data-type=float32
        VINP_DiagRLTC_mA: implementation-data-type=float32
        VINP_DiagRRTC_mA: implementation-data-type=float32
        VINP_USSConfig_raw8: implementation-data-type=u8_Array16_type
        VINP_TireSize_raw8: implementation-data-type=u8_Array16_type
        VINP_APSFunConfig_raw8: implementation-data-type=u8_Array16_type
        VINP_FlashfUnlockSingle_flg: implementation-data-type=boolean
        VINP_FlashRegenMode_enum: implementation-data-type=uint8
        VINP_FlashAmbFunEN_enum: implementation-data-type=uint8
        VINP_FlashAmbWelEN_enum: implementation-data-type=uint8
        VINP_FlashAmbDimEN_enum: implementation-data-type=uint8
        VINP_FlashAmbLinkDriSta_enum: implementation-data-type=uint8
        VINP_FlashAmbPwrWarnEN_enum: implementation-data-type=uint8
        VINP_FlashAmbODAEN_enum: implementation-data-type=uint8
        VINP_FlashAmbColorSta{1..5}_enum: implementation-data-type=uint8
        VINP_FlashAmbColorSta7_enum: implementation-data-type=uint8
        VINP_FlashAmbBrightnessSta{1..5}_enum: implementation-data-type=uint8
        VINP_FlashAmbBrightnessSta7_enum: implementation-data-type=uint8
        VINP_FlashTurnSwTSet123_enum: implementation-data-type=uint8
        VINP_FlashTurnSwTSet457_enum: implementation-data-type=uint8
        VINP_FlashAirIntZ3Sta_enum: implementation-data-type=uint8
        VINP_FlashREVentModeSta_enum: implementation-data-type=uint8
        VINP_FlashLEVentModeSta_enum: implementation-data-type=uint8
        VINP_FlashLEVentZSta_enum: implementation-data-type=uint8
        VINP_FlashCLEVentZSta_enum: implementation-data-type=uint8
        VINP_FlashREVentZSta_enum: implementation-data-type=uint8
        VINP_FlashCREVentZSta_enum: implementation-data-type=uint8
        VINP_FlashLVentEN_enum: implementation-data-type=uint8
        VINP_FlashLEVentYSta_enum: implementation-data-type=uint8
        VINP_FlashCLVentEN_enum: implementation-data-type=uint8
        VINP_FlashCLEVentYSta_enum: implementation-data-type=uint8
        VINP_FlashRVentEN_enum: implementation-data-type=uint8
        VINP_FlashREVentYSta_enum: implementation-data-type=uint8
        VINP_FlashCRVentEN_enum: implementation-data-type=uint8
        VINP_FlashCREVentYSta_enum: implementation-data-type=uint8
        VINP_FlashFGSAirIntSta_enum: implementation-data-type=uint8
        VINP_FlashFGSChSta_enum: implementation-data-type=uint8
        VINP_FlashFGSIONSWSta_enum: implementation-data-type=uint8
        VINP_FlashWalkOutLkEN_enum: implementation-data-type=uint8
        VINP_FlashWalkInUnLkEN_enum: implementation-data-type=uint8
        VINP_FlashFollowMeENFun_enum: implementation-data-type=uint8
        VINP_ResetPedalZeroPosReq_enum: implementation-data-type=uint8
        VINP_FlashPTGUserHeight{1..5}_cnt: implementation-data-type=uint16
        VINP_FlashPTGUserHeight7_cnt: implementation-data-type=uint16
        VINP_FlashPTGOpenHeight12_enum: implementation-data-type=uint8
        VINP_FlashPTGOpenHeight34_enum: implementation-data-type=uint8
        VINP_FlashPTGOpenHeight57_enum: implementation-data-type=uint8
        VINP_NewNMSpec_flg: implementation-data-type=boolean
        VINP_FlashACCLevelSta12_enum: implementation-data-type=uint8
        VINP_FlashACCLevelSta34_enum: implementation-data-type=uint8
        VINP_FlashACCLevelSta57_enum: implementation-data-type=uint8
        VINP_AutoWipHSpdEN_flg: implementation-data-type=boolean
        VINP_WipRLSCmdHoldEN_flg: implementation-data-type=boolean
        VINP_WipRLSCmdHoldTime_s: implementation-data-type=uint8
        VINP_WipRLSCmdCutEN_flg: implementation-data-type=boolean
        VINP_WipRLSCmdCutTime_s: implementation-data-type=uint8
        VINP_FlashAutoLock_enum: implementation-data-type=uint8
        VINP_FlashAutoUnlock_enum: implementation-data-type=uint8
        VINP_VehicleType_enum: implementation-data-type=uint8
        VINP_SWCType_enum: implementation-data-type=uint8
        VINP_ECUGen1_cnt: implementation-data-type=uint8
        VINP_ECUGen2_cnt: implementation-data-type=uint8
        VINP_FlashMILDIST_km: implementation-data-type=float32
        VINP_FlashWARMUPS_cnt: implementation-data-type=uint8
        VINP_FlashCLRDIST_km: implementation-data-type=float32
        VINP_FlashMILTIME_min: implementation-data-type=uint16
        VINP_FlashCLRTIME_min: implementation-data-type=uint16
        VINP_FlashNUMPSATRIPSFLTMEMCLR_cnt: implementation-data-type=uint16
        VINP_FlashODOMETER_km: implementation-data-type=float32
        VINP_FlashPSAR_sec: implementation-data-type=uint32
        VINP_FlashPSAL_sec: implementation-data-type=uint32
        VINP_FlashIPSAR_sec: implementation-data-type=uint32
        VINP_FlashIPSAL_sec: implementation-data-type=uint32
        VINP_FlashCPSAR_sec: implementation-data-type=uint32
        VINP_FlashCPSAL_sec: implementation-data-type=uint32
        VINP_FlashHVBNAH_Ahr: implementation-data-type=float32
        VINP_FlashHVBNE_kWh: implementation-data-type=float32
        VINP_FlashIGNCNTR_cnt: implementation-data-type=uint16
        VINP_FlashTNBCPSAR_Ahr: implementation-data-type=float32
        VINP_FlashTNBCPSAL_Ahr: implementation-data-type=float32
        VINP_FlashTNECPSAR_kWh: implementation-data-type=float32
        VINP_FlashTNECPSAL_kWh: implementation-data-type=float32
        VINP_FlashTEBPSAR_kWh: implementation-data-type=float32
        VINP_FlashTEBPSAL_kWh: implementation-data-type=float32
        VINP_FlashTGEOVCR_kWh: implementation-data-type=float32
        VINP_FlashTGEOVCL_kWh: implementation-data-type=float32
        VINP_FlashGECHGOVCDCR_kWh: implementation-data-type=float32
        VINP_FlashGECHGOVCDCL_kWh: implementation-data-type=float32
        VINP_FlashGECHGOVCACR_kWh: implementation-data-type=float32
        VINP_FlashGECHGOVCACL_kWh: implementation-data-type=float32
        VINP_FlashRESSV2XENNONPSAR_kWh: implementation-data-type=float32
        VINP_FlashRESSV2XENNONPSAL_kWh: implementation-data-type=float32
        VINP_FlashPKERNumerator_kphsqr: implementation-data-type=uint32
        VINP_FlashPKELNumerator_kphsqr: implementation-data-type=uint32
        VINP_FlashResetCDEODTR_km: implementation-data-type=float32
        VINP_FlashAvgBattTempPSAR_C: implementation-data-type=float32
        VINP_FlashAvgBattTempPSAL_C: implementation-data-type=float32
        VINP_FlashAvgBattTempOVCR_C: implementation-data-type=float32
        VINP_FlashAvgBattTempOVCL_C: implementation-data-type=float32
        VINP_FlashAvgBattTempOFFR_C: implementation-data-type=float32
        VINP_FlashAvgBattTempOFFL_C: implementation-data-type=float32
        VINP_FlashQTYPSATRIPSR_cnt: implementation-data-type=uint32
        VINP_FlashQTYPSATRIPSL_cnt: implementation-data-type=uint32
        VINP_FlashRESSCNTDODRNGR_cnt: implementation-data-type=u16_Array8_type
        VINP_FlashRESSCNTDODRNGL_cnt: implementation-data-type=u16_Array8_type
        VINP_FlashETMATOER_kWh: implementation-data-type=float32
        VINP_FlashETMATOEL_kWh: implementation-data-type=float32
        VINP_FlashETMBTOER_kWh: implementation-data-type=float32
        VINP_FlashETMBTOEL_kWh: implementation-data-type=float32
        VINP_FlashRESSTIMESOCPSARNGR_s: implementation-data-type=u32_Array8_type
        VINP_FlashRESSTIMESOCPSARNGL_s: implementation-data-type=u32_Array8_type
        VINP_FlashRESSTIMESOCCHGRNGR_s: implementation-data-type=u32_Array8_type
        VINP_FlashRESSTIMESOCCHGRNGL_s: implementation-data-type=u32_Array8_type
        VINP_FlashRESSTIMESOCOFFRNGR_s: implementation-data-type=u32_Array8_type
        VINP_FlashRESSTIMESOCOFFRNGL_s: implementation-data-type=u32_Array8_type
        VINP_FlashMAXBATTEMPL_C: implementation-data-type=float32
        VINP_FlashMINBATTEMPL_C: implementation-data-type=float32
        VINP_FlashAVGBATTEMPL_sec: implementation-data-type=uint32
        VINP_FlashAVGBATTEMPL_C: implementation-data-type=float32
        VINP_FlashBattTempPSAR_sec: implementation-data-type=uint32
        VINP_FlashBattTempPSAL_sec: implementation-data-type=uint32
        VINP_FlashOVCR_sec: implementation-data-type=uint32
        VINP_FlashOVCL_sec: implementation-data-type=uint32
        VINP_FlashOFFR_sec: implementation-data-type=uint32
        VINP_FlashOFFL_sec: implementation-data-type=uint32
        VINP_VinCode_cnt: implementation-data-type=u8_Array17_type
        VINP_FlashHMIKey{1..8}Func_enum: implementation-data-type=uint8
        VINP_FlashAutoWipHSpdEN_flg: implementation-data-type=boolean
        VINP_PmicBootPath_raw32: implementation-data-type=uint32
        VINP_FlashTPMModelVersion_raw: implementation-data-type=uint8
        VINP_FlashTPMModelVersionChkSum_raw: implementation-data-type=uint8
        VINP_FlashDIDModelVersion_raw: implementation-data-type=uint8
        VINP_FlashDIDModelVersionChkSum_raw: implementation-data-type=uint8
        VINP_SOCDisUsed_flg: implementation-data-type=boolean
        VINP_FlashAirIntenZone1MSet{2..5}_enum: implementation-data-type=uint8
        VINP_FlashAirIntenZone1MSet7_enum: implementation-data-type=uint8
        VINP_FlashAirIntenZone3MSet{2..5}_enum: implementation-data-type=uint8
        VINP_FlashAirIntenZone3MSet7_enum: implementation-data-type=uint8
        VINP_FlashFGSChStaSet457_enum: implementation-data-type=uint8
        VINP_FlashFGSAirIntStaSet457_enum: implementation-data-type=uint8
        VINP_FlashLEVentModeStaSet457_enum: implementation-data-type=uint8
        VINP_FlashREVentModeStaSet457_enum: implementation-data-type=uint8
        VINP_FlashLEVentZStaSet{2..5}_enum: implementation-data-type=uint8
        VINP_FlashLEVentZStaSet7_enum: implementation-data-type=uint8
        VINP_FlashCLEVentZStaSet{2..5}_enum: implementation-data-type=uint8
        VINP_FlashCLEVentZStaSet7_enum: implementation-data-type=uint8
        VINP_FlashREVentZStaSet{2..5}_enum: implementation-data-type=uint8
        VINP_FlashREVentZStaSet7_enum: implementation-data-type=uint8
        VINP_FlashCREVentZStaSet{2..5}_enum: implementation-data-type=uint8
        VINP_FlashCREVentZStaSet7_enum: implementation-data-type=uint8
        VINP_FlashLEVentYStaSet{2..5}_enum: implementation-data-type=uint8
        VINP_FlashLEVentYStaSet7_enum: implementation-data-type=uint8
        VINP_FlashCLEVentYStaSet{2..5}_enum: implementation-data-type=uint8
        VINP_FlashCLEVentYStaSet7_enum: implementation-data-type=uint8
        VINP_FlashREVentYStaSet{2..5}_enum: implementation-data-type=uint8
        VINP_FlashREVentYStaSet7_enum: implementation-data-type=uint8
        VINP_FlashCREVentYStaSet{2..5}_enum: implementation-data-type=uint8
        VINP_FlashCREVentYStaSet7_enum: implementation-data-type=uint8
        VINP_FlashACModeSet457_enum: implementation-data-type=uint8
        VINP_FlashSettempZon1Set{2..5}_enum: implementation-data-type=uint8
        VINP_FlashSettempZon1Set7_enum: implementation-data-type=uint8
        VINP_FlashJugKeepUnLZone_flg: implementation-data-type=boolean
        VINP_DrivingMode_cnt: implementation-data-type=uint8
        VINP_ModelYear_cnt: implementation-data-type=uint8
        VINP_FlashCLWinLockDrSta_enum: implementation-data-type=uint8
        VINP_CbnPreACEnaReq_enum: implementation-data-type=uint8
        VINP_PowerOffTSet_cnt: implementation-data-type=float32
        VINP_ReOutsideMirror_enum: implementation-data-type=uint8
        VINP_ReDoorLock_enum: implementation-data-type=uint16
        VINP_RePwrReqTbox_enum: implementation-data-type=uint8
        VINP_ReRadio_flg: implementation-data-type=boolean
        VINP_RemoteACTemp_C: implementation-data-type=float32
        VINP_RemoteAutoReq_flg: implementation-data-type=boolean
        VINP_TBOXRemotePW_enum: implementation-data-type=uint8
        VINP_FDCConnDrvWdwCtrlCmd_pct: implementation-data-type=uint8
        VINP_FDCConnPasWdwCtrlCmd_pct: implementation-data-type=uint8
        VINP_FDCConnRLDWdwCtrlCmd_pct: implementation-data-type=uint8
        VINP_FDCConnRRDWdwCtrlCmd_pct: implementation-data-type=uint8
        VINP_CAN{1..6}BusError_flg: implementation-data-type=boolean
    BINP_TPMS_outputs: category=STRUCTURE
      52 x element, all with category=TYPE_REFERENCE:
        VINP_TPMSDataIn_flg: implementation-data-type=boolean
        VINP_TPMSID_raw: implementation-data-type=uint32
        VINP_TPMSPressure_raw: implementation-data-type=uint8
        VINP_TPMSTemp_raw: implementation-data-type=uint8
        VINP_TPMSSta_enum: implementation-data-type=uint8
        VINP_TPMSPressureMi_raw: implementation-data-type=uint8
        VINP_TPMSCRC_crc: implementation-data-type=uint8
        VINP_TPMSCRCCalc_crc: implementation-data-type=uint8
        VINP_TPMSFAT_flg: implementation-data-type=boolean
        VINP_TPMSBattLow_flg: implementation-data-type=boolean
        VINP_TPMSStorge_flg: implementation-data-type=boolean
        VINP_LFID_raw: implementation-data-type=uint32
        VINP_RFID_raw: implementation-data-type=uint32
        VINP_LRID_raw: implementation-data-type=uint32
        VINP_RRID_raw: implementation-data-type=uint32
        VINP_ChkStorge_flg: implementation-data-type=boolean
        VINP_ChkLFID_raw: implementation-data-type=uint32
        VINP_ChkRFID_raw: implementation-data-type=uint32
        VINP_ChkLRID_raw: implementation-data-type=uint32
        VINP_ChkRRID_raw: implementation-data-type=uint32
        VINP_FlashLFSensorFail_flg: implementation-data-type=boolean
        VINP_FlashRFSensorFail_flg: implementation-data-type=boolean
        VINP_FlashLRSensorFail_flg: implementation-data-type=boolean
        VINP_FlashRRSensorFail_flg: implementation-data-type=boolean
        VINP_FlashLFWheelPSW_raw8: implementation-data-type=uint8
        VINP_FlashRFWheelPSW_raw8: implementation-data-type=uint8
        VINP_FlashLRWheelPSW_raw8: implementation-data-type=uint8
        VINP_FlashRRWheelPSW_raw8: implementation-data-type=uint8
        VINP_FlashLFPindi_enum: implementation-data-type=uint8
        VINP_FlashRFPindi_enum: implementation-data-type=uint8
        VINP_FlashLRPindi_enum: implementation-data-type=uint8
        VINP_FlashRRPindi_enum: implementation-data-type=uint8
        VINP_FlashLFP20_raw8: implementation-data-type=uint8
        VINP_FlashRFP20_raw8: implementation-data-type=uint8
        VINP_FlashLRP20_raw8: implementation-data-type=uint8
        VINP_FlashRRP20_raw8: implementation-data-type=uint8
        VINP_FlashLFWheelPress_raw8: implementation-data-type=uint8
        VINP_FlashRFWheelPress_raw8: implementation-data-type=uint8
        VINP_FlashLRWheelPress_raw8: implementation-data-type=uint8
        VINP_FlashRRWheelPress_raw8: implementation-data-type=uint8
        VINP_FlashLFWheelTemp_C: implementation-data-type=uint8
        VINP_FlashRFWheelTemp_C: implementation-data-type=uint8
        VINP_FlashLRWheelTemp_C: implementation-data-type=uint8
        VINP_FlashRRWheelTemp_C: implementation-data-type=uint8
        VINP_FlashunlearnSfali_flg: implementation-data-type=boolean
        VINP_S{1..4}ID_raw: implementation-data-type=uint32
        VINP_Prepresstemptrust_flg: implementation-data-type=boolean
        VINP_TPMSSensorIDRegSta_enum: implementation-data-type=uint8
        VINP_TPMSTrigger_flg: implementation-data-type=boolean
    u8_Array16_type: category=ARRAY
      element u8_Array16: category=VALUE, array-size=16, array-size-semantics=FIXED-SIZE, base-type=uint8
    u16_Array8_type: category=ARRAY
      element u16_Array8: category=VALUE, array-size=8, array-size-semantics=FIXED-SIZE, base-type=uint16
    u8_Array8_type: category=ARRAY
      element u8_Array8: category=VALUE, array-size=8, array-size-semantics=FIXED-SIZE, base-type=uint8
    u32_Array8_type: category=ARRAY
      element u32_Array8: category=VALUE, array-size=8, array-size-semantics=FIXED-SIZE, base-type=uint32
    u8_Array17_type: category=ARRAY
      element u8_Array17: category=VALUE, array-size=17, array-size-semantics=FIXED-SIZE, base-type=uint8
package /Interface_INP_ARPkg
  13 x sender receiver interface:
    IF_BINP_CAN1_outputs
      data BINP_CAN1_outputs: type=BINP_CAN1_outputs
    IF_BINP_CAN2_outputs
      data BINP_CAN2_outputs: type=BINP_CAN2_outputs
    IF_BINP_CAN3_outputs
      data BINP_CAN3_outputs: type=BINP_CAN3_outputs
    IF_BINP_CAN4_outputs
      data BINP_CAN4_outputs: type=BINP_CAN4_outputs
    IF_BINP_CAN5_outputs
      data BINP_CAN5_outputs: type=BINP_CAN5_outputs
    IF_BINP_CAN6_outputs
      data BINP_CAN6_outputs: type=BINP_CAN6_outputs
    IF_BINP_APM_outputs
      data BINP_APM_outputs: type=BINP_APM_outputs
    IF_BINP_DDM_outputs
      data BINP_DDM_outputs: type=BINP_DDM_outputs
    IF_BINP_DKC_outputs
      data BINP_DKC_outputs: type=BINP_DKC_outputs
    IF_BINP_GPIO_outputs
      data BINP_GPIO_outputs: type=BINP_GPIO_outputs
    IF_BINP_IMU_outputs
      data BINP_IMU_outputs: type=BINP_IMU_outputs
    IF_BINP_SYS_outputs
      data BINP_SYS_outputs: type=BINP_SYS_outputs
    IF_BINP_TPMS_outputs
      data BINP_TPMS_outputs: type=BINP_TPMS_outputs
package /SWC_INP_ARPkg
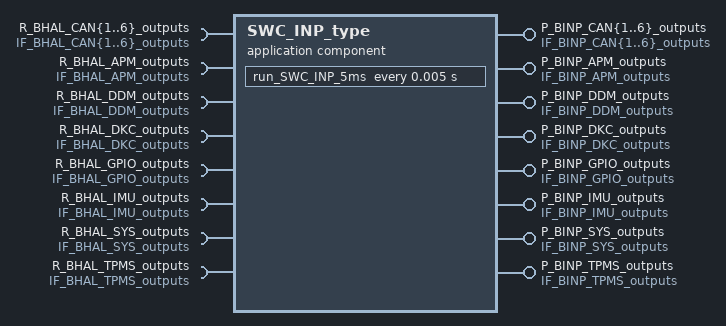
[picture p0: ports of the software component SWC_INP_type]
  application sw component type SWC_INP_type
    13 x provide port:
      P_BINP_CAN{1..6}_outputs: provided-interface=IF_BINP_CAN{1..6}_outputs
      P_BINP_APM_outputs: provided-interface=IF_BINP_APM_outputs
      P_BINP_DDM_outputs: provided-interface=IF_BINP_DDM_outputs
      P_BINP_DKC_outputs: provided-interface=IF_BINP_DKC_outputs
      P_BINP_GPIO_outputs: provided-interface=IF_BINP_GPIO_outputs
      P_BINP_IMU_outputs: provided-interface=IF_BINP_IMU_outputs
      P_BINP_SYS_outputs: provided-interface=IF_BINP_SYS_outputs
      P_BINP_TPMS_outputs: provided-interface=IF_BINP_TPMS_outputs
    13 x require port:
      R_BHAL_CAN{1..6}_outputs: required-interface=IF_BHAL_CAN{1..6}_outputs
      R_BHAL_APM_outputs: required-interface=IF_BHAL_APM_outputs
      R_BHAL_DDM_outputs: required-interface=IF_BHAL_DDM_outputs
      R_BHAL_DKC_outputs: required-interface=IF_BHAL_DKC_outputs
      R_BHAL_GPIO_outputs: required-interface=IF_BHAL_GPIO_outputs
      R_BHAL_IMU_outputs: required-interface=IF_BHAL_IMU_outputs
      R_BHAL_SYS_outputs: required-interface=IF_BHAL_SYS_outputs
      R_BHAL_TPMS_outputs: required-interface=IF_BHAL_TPMS_outputs
    behavior SWC_INP_type_IB: handle-termination-and-restart=NO-SUPPORT
      timing event TE_INP_5ms: start-on-event=run_SWC_INP_5ms, period=0.005
      runnable run_SWC_INP_5ms
        data-receive-point-by-arguments:
          13 x access:
            drparg_BHAL_CAN{1..6}_outputs: accessed-variable=R_BHAL_CAN{1..6}_outputs.BHAL_CAN{1..6}_outputs
            drparg_BHAL_APM_outputs: accessed-variable=R_BHAL_APM_outputs.BHAL_APM_outputs
            drparg_BHAL_DDM_outputs: accessed-variable=R_BHAL_DDM_outputs.BHAL_DDM_outputs
            drparg_BHAL_DKC_outputs: accessed-variable=R_BHAL_DKC_outputs.BHAL_DKC_outputs
            drparg_BHAL_GPIO_outputs: accessed-variable=R_BHAL_GPIO_outputs.BHAL_GPIO_outputs
            drparg_BHAL_IMU_outputs: accessed-variable=R_BHAL_IMU_outputs.BHAL_IMU_outputs
            drparg_BHAL_SYS_outputs: accessed-variable=R_BHAL_SYS_outputs.BHAL_SYS_outputs
            drparg_BHAL_TPMS_outputs: accessed-variable=R_BHAL_TPMS_outputs.BHAL_TPMS_outputs
        data-send-points:
          13 x access:
            dsp_BINP_CAN{1..6}_outputs: accessed-variable=P_BINP_CAN{1..6}_outputs.BINP_CAN{1..6}_outputs
            dsp_BINP_APM_outputs: accessed-variable=P_BINP_APM_outputs.BINP_APM_outputs
            dsp_BINP_DDM_outputs: accessed-variable=P_BINP_DDM_outputs.BINP_DDM_outputs
            dsp_BINP_DKC_outputs: accessed-variable=P_BINP_DKC_outputs.BINP_DKC_outputs
            dsp_BINP_GPIO_outputs: accessed-variable=P_BINP_GPIO_outputs.BINP_GPIO_outputs
            dsp_BINP_IMU_outputs: accessed-variable=P_BINP_IMU_outputs.BINP_IMU_outputs
            dsp_BINP_SYS_outputs: accessed-variable=P_BINP_SYS_outputs.BINP_SYS_outputs
            dsp_BINP_TPMS_outputs: accessed-variable=P_BINP_TPMS_outputs.BINP_TPMS_outputs
